VERSION "..\..\trunk\components\winTestMT\code\canApi\dbcFiles\canBus_01.dbc, created by Octave and generateRandomDbc.m on 21-Feb-2017"

NS_ :

BS_:

BU_: ECU

BO_ 1706 frame_1706: 8 Vector__XXX
  SG_ checksum_57_8 : 63|8@0+ (1.0,0.0) [0.0|255.0] "" ECU
  SG_ sig_2_29 : 2|29@1+ (1.0000000000000014E-12,0.0) [0.0|5.368709100000008E-4] "W" ECU
  SG_ sig_0_2 : 0|2@1+ (1.0,0.0) [0.0|3.0] "" ECU
  SG_ sig_42_14 : 42|14@1- (1.0,0.0) [-8192.0|8190.0] "" ECU
  SG_ sig_34_6 : 34|6@1+ (1.0,0.0) [0.0|62.0] "" ECU
  SG_ sig_33_2 : 33|2@0- (1.0,0.0) [-2.0|1.0] "" ECU

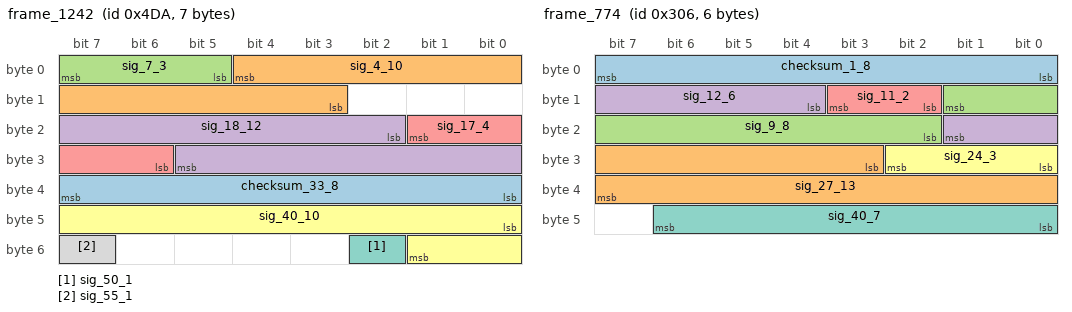
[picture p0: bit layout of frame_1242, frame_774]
BO_ 1242 frame_1242: 7 Vector__XXX
  SG_ checksum_33_8 : 39|8@0+ (1.0,0.0) [0.0|255.0] "" ECU
  SG_ sig_4_10 : 4|10@0- (1.0000000000000006E-6,0.0) [-5.120000000000003E-4|5.100000000000003E-4] "V" ECU
  SG_ sig_7_3 : 7|3@0- (1.0,0.0) [-4.0|2.0] "" ECU
  SG_ sig_18_12 : 18|12@1+ (0.0010000000000000002,-3.1622776601683795) [-3.1622776601683795|0.9317223398316217] "s" ECU
  SG_ sig_17_4 : 17|4@0- (1.0,0.0) [-8.0|6.0] "" ECU
  SG_ sig_40_10 : 40|10@1+ (1.0000000000000005E-4,0.03162277660168379) [0.03162277660168379|0.13382277660168385] "W" ECU
  SG_ sig_50_1 : 50|1@1+ (1.0,0.0) [0.0|1.0] "" ECU
  SG_ sig_55_1 : 55|1@0+ (1.0,0.0) [0.0|1.0] "" ECU

BO_ 774 frame_774: 6 Vector__XXX
  SG_ checksum_1_8 : 7|8@0+ (1.0,0.0) [0.0|255.0] "" ECU
  SG_ sig_27_13 : 27|13@1- (1.0000000000000005E-4,0.0) [-0.4096000000000002|0.4094000000000002] "W" ECU
  SG_ sig_9_8 : 9|8@0- (1.0000000000000006E-5,0.0) [-0.0012800000000000008|0.0012600000000000007] "kWh" ECU
  SG_ sig_12_6 : 12|6@1- (1.0,0.0) [-32.0|30.0] "" ECU
  SG_ sig_11_2 : 11|2@0- (1.0,0.0) [-2.0|1.0] "" ECU
  SG_ sig_24_3 : 24|3@1+ (1.0,0.0) [0.0|6.0] "" ECU
  SG_ sig_40_7 : 40|7@1- (0.010000000000000002,0.31622776601683794) [-0.3237722339831622|0.9362277660168381] "s" ECU

BO_ 2044 frame_2044: 4 ECU
  SG_ checksum_17_8 : 16|8@1+ (1.0,0.0) [0.0|255.0] "" Vector__XXX
  SG_ sig_0_14 : 0|14@1- (1.0000000000000008E-8,3.1622776601683795E-5) [-5.0297223398316274E-5|1.1352277660168385E-4] "m/s^2" Vector__XXX
  SG_ sig_15_2 : 15|2@0- (1.0,0.0) [-2.0|1.0] "" Vector__XXX
  SG_ sig_31_2 : 31|2@0- (1.0,0.0) [-2.0|1.0] "" Vector__XXX
  SG_ sig_24_1 : 24|1@1+ (1.0,0.0) [0.0|1.0] "" Vector__XXX

BO_ 1907 frame_1907: 7 Vector__XXX
  SG_ checksum_1_8 : 7|8@0+ (1.0,0.0) [0.0|255.0] "" ECU
  SG_ sig_31_1 : 31|1@0+ (1.0,0.0) [0.0|1.0] "" ECU
  SG_ sig_15_16 : 15|16@0- (0.0010000000000000002,-31.622776601683793) [-64.3907766016838|1.1432233983162128] "m/s^2" ECU
  SG_ sig_25_24 : 25|24@0- (1.0000000000000005E-4,316.22776601683796) [-522.6330339831625|1155.0883660168383] "W" ECU
  SG_ sig_30_5 : 30|5@0- (1.0,0.0) [-16.0|14.0] "" ECU

BO_ 594 frame_594: 7 Vector__XXX
  SG_ checksum_33_8 : 39|8@0+ (1.0,0.0) [0.0|255.0] "" ECU
  SG_ sig_5_25 : 5|25@1+ (0.0010000000000000002,0.0) [0.0|33554.43000000001] "s" ECU
  SG_ sig_1_4 : 1|4@1- (1.0,3.1622776601683795) [-4.83772233983162|9.16227766016838] "A" ECU
  SG_ sig_0_1 : 0|1@0+ (1.0,0.0) [0.0|1.0] "" ECU
  SG_ sig_30_2 : 30|2@1- (1.0,0.0) [-2.0|1.0] "" ECU
  SG_ sig_47_16 : 47|16@0- (1.0000000000000007E-7,0.0) [-0.0032768000000000025|0.0032766000000000023] "m/s^2" ECU

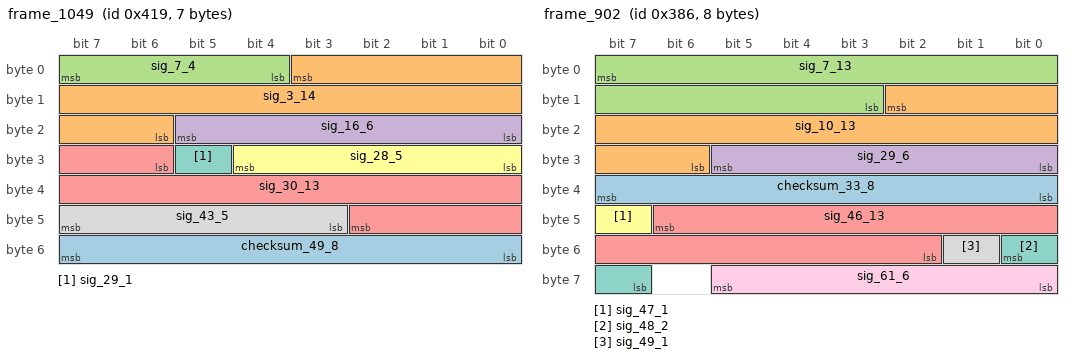
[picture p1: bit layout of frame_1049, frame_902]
BO_ 1049 frame_1049: 7 ECU
  SG_ checksum_49_8 : 48|8@1+ (1.0,0.0) [0.0|255.0] "" Vector__XXX
  SG_ sig_3_14 : 3|14@0+ (0.0010000000000000002,3.1622776601683795) [3.1622776601683795|19.544277660168383] "A" Vector__XXX
  SG_ sig_7_4 : 7|4@0+ (1.0,0.0) [0.0|14.0] "" Vector__XXX
  SG_ sig_16_6 : 16|6@1- (1.0,0.0) [-32.0|30.0] "" Vector__XXX
  SG_ sig_30_13 : 30|13@1+ (1.0,3162.2776601683795) [3162.2776601683795|11352.27766016838] "s" Vector__XXX
  SG_ sig_28_5 : 28|5@0- (1.0,0.0) [-16.0|14.0] "" Vector__XXX
  SG_ sig_29_1 : 29|1@0+ (1.0,0.0) [0.0|1.0] "" Vector__XXX
  SG_ sig_43_5 : 43|5@1+ (100.0,0.0) [0.0|3000.0] "km/h" Vector__XXX

BO_ 1207 frame_1207: 7 Vector__XXX
  SG_ checksum_1_8 : 0|8@1+ (1.0,0.0) [0.0|255.0] "" ECU
  SG_ sig_19_31 : 19|31@1- (1.0000000000000011E-10,0.0) [-0.10737418240000011|0.10737418220000011] "V" ECU
  SG_ sig_9_10 : 9|10@1- (100.0,0.0) [-51200.0|51000.0] "km/h" ECU
  SG_ sig_8_1 : 8|1@0+ (1.0,0.0) [0.0|1.0] "" ECU
  SG_ sig_55_4 : 55|4@0- (1.0000000000000006E-6,-3.162277660168379E-6) [-1.1162277660168384E-5|2.8377223398316243E-6] "km/h" ECU

BO_ 902 frame_902: 8 Vector__XXX
  SG_ checksum_33_8 : 39|8@0+ (1.0,0.0) [0.0|255.0] "" ECU
  SG_ sig_10_13 : 10|13@0- (1.0000000000000009E-9,3.162277660168379E-6) [-9.337223398316245E-7|7.256277660168383E-6] "W" ECU
  SG_ sig_7_13 : 7|13@0- (1.0,0.0) [-4096.0|4094.0] "" ECU
  SG_ sig_29_6 : 29|6@0+ (0.1,3.1622776601683795) [3.1622776601683795|9.36227766016838] "kWh" ECU
  SG_ sig_46_13 : 46|13@0+ (0.1,0.0) [0.0|819.0] "m/s^2" ECU
  SG_ sig_47_1 : 47|1@0+ (1.0,0.0) [0.0|1.0] "" ECU
  SG_ sig_48_2 : 48|2@0+ (1.0,0.0) [0.0|3.0] "" ECU
  SG_ sig_49_1 : 49|1@0+ (1.0,0.0) [0.0|1.0] "" ECU
  SG_ sig_61_6 : 61|6@0+ (1.0,0.0) [0.0|62.0] "" ECU

BO_ 1834 frame_1834: 6 ECU
  SG_ checksum_17_8 : 16|8@1+ (1.0,0.0) [0.0|255.0] "" Vector__XXX
  SG_ sig_7_16 : 7|16@0+ (1.0000000000000009E-9,0.0) [0.0|6.553400000000005E-5] "m/s^2" Vector__XXX
  SG_ sig_28_20 : 28|20@0+ (1.0000000000000007E-7,-0.03162277660168379) [-0.03162277660168379|0.07323462339831628] "W" Vector__XXX
  SG_ sig_29_3 : 29|3@1+ (1.0,0.0) [0.0|6.0] "" Vector__XXX
  SG_ sig_40_1 : 40|1@1+ (1.0,0.0) [0.0|1.0] "" Vector__XXX

BO_ 609 frame_609: 5 Vector__XXX
  SG_ checksum_1_8 : 7|8@0+ (1.0,0.0) [0.0|255.0] "" ECU
  SG_ sig_22_5 : 22|5@0- (1.0,0.0) [-16.0|14.0] "" ECU
  SG_ sig_8_8 : 8|8@1- (10.0,0.0) [-1280.0|1260.0] "km/h" ECU
  SG_ sig_16_2 : 16|2@1+ (1.0,0.0) [0.0|3.0] "" ECU
  SG_ sig_23_16 : 23|16@1+ (1.0,0.0) [0.0|65534.0] "" ECU

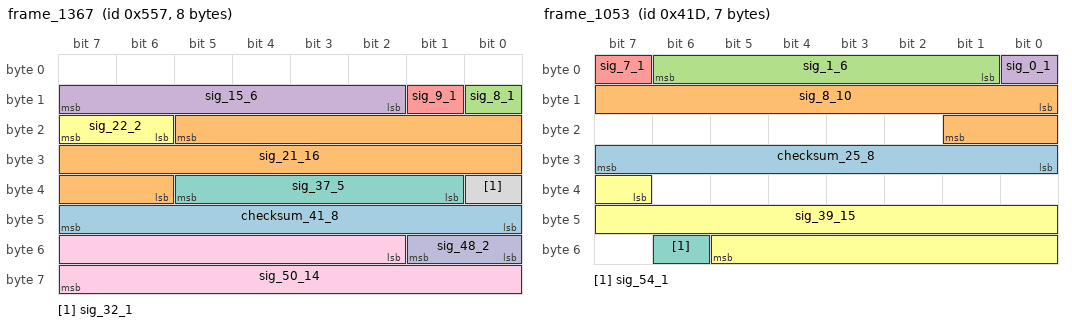
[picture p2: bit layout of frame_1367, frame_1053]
BO_ 1367 frame_1367: 8 Vector__XXX
  SG_ checksum_41_8 : 40|8@1+ (1.0,0.0) [0.0|255.0] "" ECU
  SG_ sig_21_16 : 21|16@0- (1.0000000000000005E-4,0.0) [-3.2768000000000015|3.2766000000000015] "W" ECU
  SG_ sig_8_1 : 8|1@1+ (1.0,0.0) [0.0|1.0] "" ECU
  SG_ sig_15_6 : 15|6@0- (100.0,3162.2776601683795) [-37.7223398316205|6162.27766016838] "s" ECU
  SG_ sig_9_1 : 9|1@0+ (1.0,0.0) [0.0|1.0] "" ECU
  SG_ sig_22_2 : 22|2@1+ (1.0,0.0) [0.0|3.0] "" ECU
  SG_ sig_37_5 : 37|5@0+ (1.0,0.0) [0.0|30.0] "" ECU
  SG_ sig_32_1 : 32|1@1+ (1.0,0.0) [0.0|1.0] "" ECU
  SG_ sig_50_14 : 50|14@1+ (0.010000000000000002,0.0) [0.0|163.82000000000002] "m/s^2" ECU
  SG_ sig_48_2 : 48|2@1- (1.0,0.0) [-2.0|1.0] "" ECU

BO_ 1053 frame_1053: 7 ECU
  SG_ checksum_25_8 : 24|8@1+ (1.0,0.0) [0.0|255.0] "" Vector__XXX
  SG_ sig_8_10 : 8|10@1- (1.0,0.0) [-512.0|510.0] "" Vector__XXX
  SG_ sig_1_6 : 1|6@1- (1.0,0.0) [-32.0|30.0] "" Vector__XXX
  SG_ sig_0_1 : 0|1@1+ (1.0,0.0) [0.0|1.0] "" Vector__XXX
  SG_ sig_7_1 : 7|1@1+ (1.0,0.0) [0.0|1.0] "" Vector__XXX
  SG_ sig_39_15 : 39|15@1+ (1.0000000000000005E-4,0.0) [0.0|3.2766000000000015] "m/s^2" Vector__XXX
  SG_ sig_54_1 : 54|1@1+ (1.0,0.0) [0.0|1.0] "" Vector__XXX

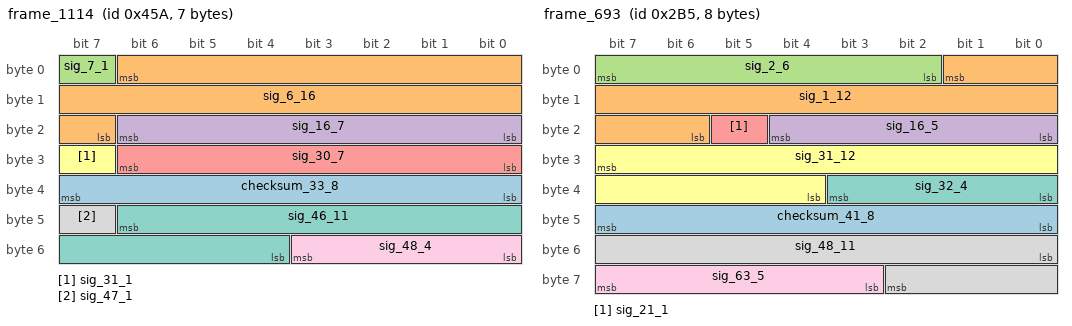
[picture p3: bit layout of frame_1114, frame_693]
BO_ 1114 frame_1114: 7 Vector__XXX
  SG_ checksum_33_8 : 32|8@1+ (1.0,0.0) [0.0|255.0] "" ECU
  SG_ sig_6_16 : 6|16@0- (1.0000000000000007E-7,0.0) [-0.0032768000000000025|0.0032766000000000023] "s" ECU
  SG_ sig_7_1 : 7|1@1+ (1.0,0.0) [0.0|1.0] "" ECU
  SG_ sig_16_7 : 16|7@1- (0.0010000000000000002,0.0) [-0.06400000000000002|0.06200000000000001] "kWh" ECU
  SG_ sig_30_7 : 30|7@0+ (1.0000000000000005E-4,0.0) [0.0|0.012600000000000005] "V" ECU
  SG_ sig_31_1 : 31|1@1+ (1.0,0.0) [0.0|1.0] "" ECU
  SG_ sig_46_11 : 46|11@0+ (1.0000000000000008E-8,0.0) [0.0|2.0460000000000018E-5] "m/s^2" ECU
  SG_ sig_47_1 : 47|1@0+ (1.0,0.0) [0.0|1.0] "" ECU
  SG_ sig_48_4 : 48|4@1+ (10000.0,-31622.776601683792) [-31622.776601683792|108377.22339831622] "V" ECU

BO_ 693 frame_693: 8 ECU
  SG_ checksum_41_8 : 40|8@1+ (1.0,0.0) [0.0|255.0] "" Vector__XXX
  SG_ sig_1_12 : 1|12@0- (1.0000000000000006E-6,0.0) [-0.002048000000000001|0.0020460000000000014] "V" Vector__XXX
  SG_ sig_2_6 : 2|6@1- (1.0000000000000006E-6,-3.1622776601683795E-5) [-6.362277660168381E-5|-1.6227766016837776E-6] "m/s^2" Vector__XXX
  SG_ sig_16_5 : 16|5@1- (1.0,0.0) [-16.0|14.0] "" Vector__XXX
  SG_ sig_21_1 : 21|1@0+ (1.0,0.0) [0.0|1.0] "" Vector__XXX
  SG_ sig_31_12 : 31|12@0+ (0.1,0.0) [0.0|409.40000000000003] "V" Vector__XXX
  SG_ sig_32_4 : 32|4@1- (1000.0,0.0) [-8000.0|6000.0] "kWh" Vector__XXX
  SG_ sig_48_11 : 48|11@1- (1.0,0.0) [-1024.0|1022.0] "" Vector__XXX
  SG_ sig_63_5 : 63|5@0+ (0.010000000000000002,0.0) [0.0|0.30000000000000004] "m/s^2" Vector__XXX

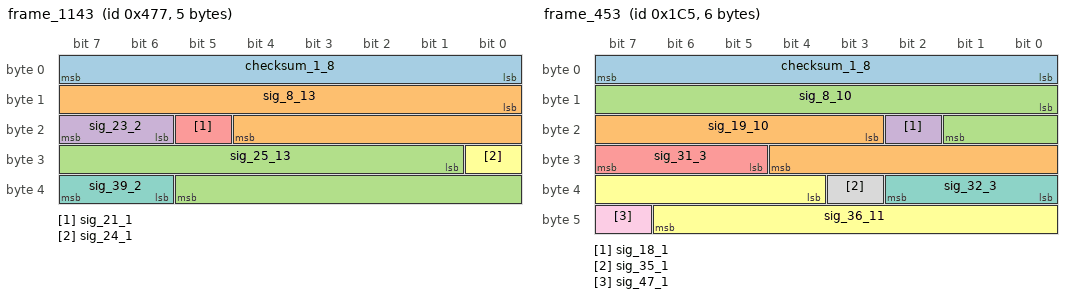
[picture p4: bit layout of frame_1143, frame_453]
BO_ 1143 frame_1143: 5 ECU
  SG_ checksum_1_8 : 7|8@0+ (1.0,0.0) [0.0|255.0] "" Vector__XXX
  SG_ sig_8_13 : 8|13@1+ (1.0000000000000005E-4,0.31622776601683794) [0.31622776601683794|1.1352277660168384] "A" Vector__XXX
  SG_ sig_25_13 : 25|13@1- (1.0000000000000009E-9,0.0) [-4.096000000000004E-6|4.0940000000000035E-6] "m/s^2" Vector__XXX
  SG_ sig_23_2 : 23|2@0- (1.0,0.0) [-2.0|1.0] "" Vector__XXX
  SG_ sig_21_1 : 21|1@0+ (1.0,0.0) [0.0|1.0] "" Vector__XXX
  SG_ sig_24_1 : 24|1@1+ (1.0,0.0) [0.0|1.0] "" Vector__XXX
  SG_ sig_39_2 : 39|2@0- (1.0,0.0) [-2.0|1.0] "" Vector__XXX

BO_ 667 frame_667: 7 Vector__XXX
  SG_ checksum_1_8 : 0|8@1+ (1.0,0.0) [0.0|255.0] "" ECU
  SG_ sig_22_35 : 22|35@0+ (1.0000000000000007E-7,3162.2776601683795) [3162.2776601683795|6598.251496768382] "A" ECU
  SG_ sig_9_6 : 9|6@1+ (0.1,3.1622776601683795) [3.1622776601683795|9.36227766016838] "s" ECU
  SG_ sig_48_3 : 48|3@1- (1.0,0.0) [-4.0|2.0] "" ECU

BO_ 453 frame_453: 6 ECU
  SG_ checksum_1_8 : 7|8@0+ (1.0,0.0) [0.0|255.0] "" Vector__XXX
  SG_ sig_19_10 : 19|10@1+ (1.0000000000000007E-7,-3.1622776601683795E-5) [-3.1622776601683795E-5|7.057722339831628E-5] "A" Vector__XXX
  SG_ sig_8_10 : 8|10@1+ (1.0,0.0) [0.0|1022.0] "" Vector__XXX
  SG_ sig_18_1 : 18|1@1+ (1.0,0.0) [0.0|1.0] "" Vector__XXX
  SG_ sig_31_3 : 31|3@0- (1.0,0.0) [-4.0|2.0] "" Vector__XXX
  SG_ sig_36_11 : 36|11@1+ (1.0000000000000006E-5,-0.0031622776601683794) [-0.0031622776601683794|0.017297722339831633] "m/s^2" Vector__XXX
  SG_ sig_32_3 : 32|3@1- (1.0,0.0) [-4.0|2.0] "" Vector__XXX
  SG_ sig_35_1 : 35|1@0+ (1.0,0.0) [0.0|1.0] "" Vector__XXX
  SG_ sig_47_1 : 47|1@0+ (1.0,0.0) [0.0|1.0] "" Vector__XXX

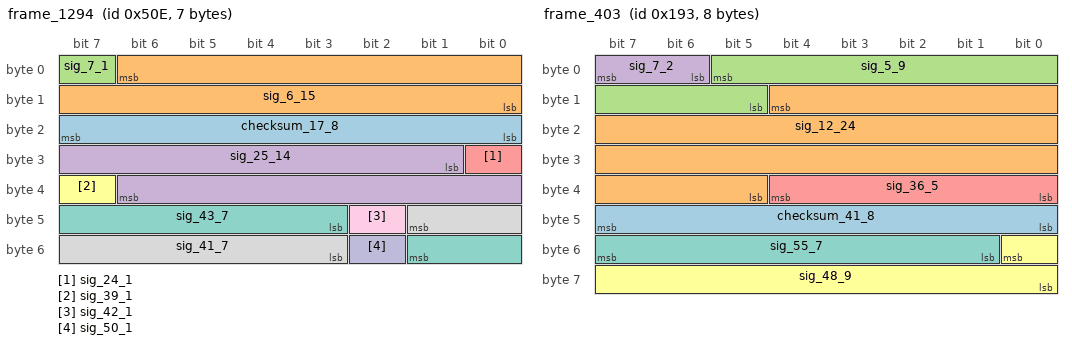
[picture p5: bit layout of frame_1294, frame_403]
BO_ 1294 frame_1294: 7 Vector__XXX
  SG_ checksum_17_8 : 23|8@0+ (1.0,0.0) [0.0|255.0] "" ECU
  SG_ sig_6_15 : 6|15@0- (0.010000000000000002,0.0) [-163.84000000000003|163.82000000000002] "V" ECU
  SG_ sig_7_1 : 7|1@0+ (1.0,0.0) [0.0|1.0] "" ECU
  SG_ sig_25_14 : 25|14@1+ (0.010000000000000002,0.0) [0.0|163.82000000000002] "kWh" ECU
  SG_ sig_24_1 : 24|1@1+ (1.0,0.0) [0.0|1.0] "" ECU
  SG_ sig_39_1 : 39|1@0+ (1.0,0.0) [0.0|1.0] "" ECU
  SG_ sig_43_7 : 43|7@1- (1.0000000000000005E-4,-0.0031622776601683794) [-0.009562277660168383|0.003037722339831623] "m/s^2" ECU
  SG_ sig_41_7 : 41|7@0- (1.0000000000000006E-6,0.0) [-6.400000000000004E-5|6.200000000000004E-5] "m/s^2" ECU
  SG_ sig_42_1 : 42|1@0+ (1.0,0.0) [0.0|1.0] "" ECU
  SG_ sig_50_1 : 50|1@0+ (1.0,0.0) [0.0|1.0] "" ECU

BO_ 403 frame_403: 8 ECU
  SG_ checksum_41_8 : 47|8@0+ (1.0,0.0) [0.0|255.0] "" Vector__XXX
  SG_ sig_12_24 : 12|24@0+ (1.0000000000000014E-12,-3.162277660168379E-6) [-3.162277660168379E-6|1.3614936339831645E-5] "s" Vector__XXX
  SG_ sig_5_9 : 5|9@0- (1.0000000000000007E-7,0.0) [-2.560000000000002E-5|2.5400000000000018E-5] "m/s^2" Vector__XXX
  SG_ sig_7_2 : 7|2@0+ (1.0,0.0) [0.0|3.0] "" Vector__XXX
  SG_ sig_36_5 : 36|5@0- (1.0,0.0) [-16.0|14.0] "" Vector__XXX
  SG_ sig_48_9 : 48|9@0+ (1.0000000000000005E-4,-0.03162277660168379) [-0.03162277660168379|0.019377223398316233] "W" Vector__XXX
  SG_ sig_55_7 : 55|7@0+ (1.0,-31.622776601683793) [-31.622776601683793|94.3772233983162] "V" Vector__XXX

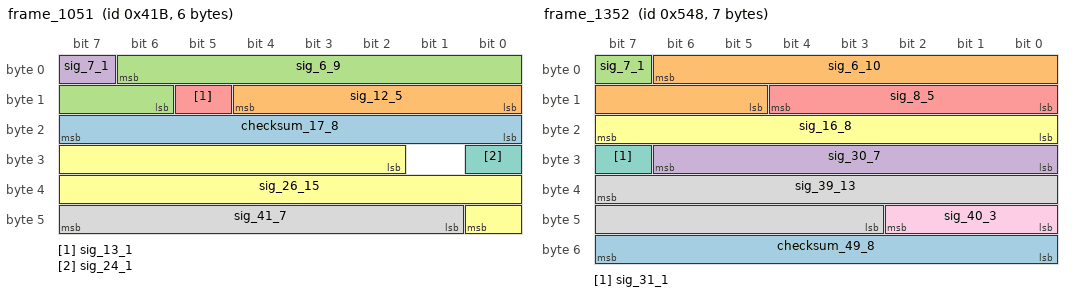
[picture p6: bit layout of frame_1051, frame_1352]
BO_ 1051 frame_1051: 6 Vector__XXX
  SG_ checksum_17_8 : 23|8@0+ (1.0,0.0) [0.0|255.0] "" ECU
  SG_ sig_12_5 : 12|5@0+ (1.0,0.0) [0.0|30.0] "km/h" ECU
  SG_ sig_6_9 : 6|9@0- (1.0000000000000007E-7,0.0) [-2.560000000000002E-5|2.5400000000000018E-5] "m/s^2" ECU
  SG_ sig_7_1 : 7|1@0+ (1.0,0.0) [0.0|1.0] "" ECU
  SG_ sig_13_1 : 13|1@0+ (1.0,0.0) [0.0|1.0] "" ECU
  SG_ sig_26_15 : 26|15@1- (1.0,0.0) [-16384.0|16382.0] "" ECU
  SG_ sig_24_1 : 24|1@0+ (1.0,0.0) [0.0|1.0] "" ECU
  SG_ sig_41_7 : 41|7@1+ (1.0000000000000005E-4,0.0031622776601683794) [0.0031622776601683794|0.015762277660168383] "A" ECU

BO_ 1352 frame_1352: 7 Vector__XXX
  SG_ checksum_49_8 : 48|8@1+ (1.0,0.0) [0.0|255.0] "" ECU
  SG_ sig_6_10 : 6|10@0+ (1.0000000000000006E-6,0.0) [0.0|0.0010220000000000006] "W" ECU
  SG_ sig_7_1 : 7|1@0+ (1.0,0.0) [0.0|1.0] "" ECU
  SG_ sig_30_7 : 30|7@0+ (1.0,0.0) [0.0|126.0] "" ECU
  SG_ sig_8_5 : 8|5@1+ (1.0,0.0) [0.0|30.0] "kWh" ECU
  SG_ sig_16_8 : 16|8@1+ (0.010000000000000002,0.31622776601683794) [0.31622776601683794|2.8562277660168385] "m/s^2" ECU
  SG_ sig_31_1 : 31|1@0+ (1.0,0.0) [0.0|1.0] "" ECU
  SG_ sig_39_13 : 39|13@0- (1.0000000000000007E-7,-3.1622776601683794E-4) [-7.258277660168382E-4|9.317223398316236E-5] "km/h" ECU
  SG_ sig_40_3 : 40|3@1- (1.0,0.0) [-4.0|2.0] "" ECU

BO_ 1140 frame_1140: 7 Vector__XXX
  SG_ checksum_33_8 : 32|8@1+ (1.0,0.0) [0.0|255.0] "" ECU
  SG_ sig_16_14 : 16|14@1- (1.0000000000000005E-4,0.31622776601683794) [-0.5029722339831624|1.1352277660168384] "kWh" ECU
  SG_ sig_3_11 : 3|11@1- (1.0,0.0) [-1024.0|1022.0] "" ECU
  SG_ sig_0_3 : 0|3@0+ (1.0,0.0) [0.0|6.0] "" ECU
  SG_ sig_40_16 : 40|16@1- (1.0000000000000007E-7,0.0) [-0.0032768000000000025|0.0032766000000000023] "A" ECU

BO_ 652 frame_652: 6 Vector__XXX
  SG_ checksum_1_8 : 7|8@0+ (1.0,0.0) [0.0|255.0] "" ECU
  SG_ sig_10_2 : 10|2@1+ (1.0,0.0) [0.0|3.0] "" ECU
  SG_ sig_9_2 : 9|2@0+ (1.0,0.0) [0.0|3.0] "" ECU
  SG_ sig_34_11 : 34|11@1+ (1.0000000000000006E-5,0.0031622776601683794) [0.0031622776601683794|0.023622277660168393] "W" ECU
  SG_ sig_32_2 : 32|2@1- (1.0,0.0) [-2.0|1.0] "" ECU
  SG_ sig_47_3 : 47|3@0- (1.0,0.0) [-4.0|2.0] "" ECU

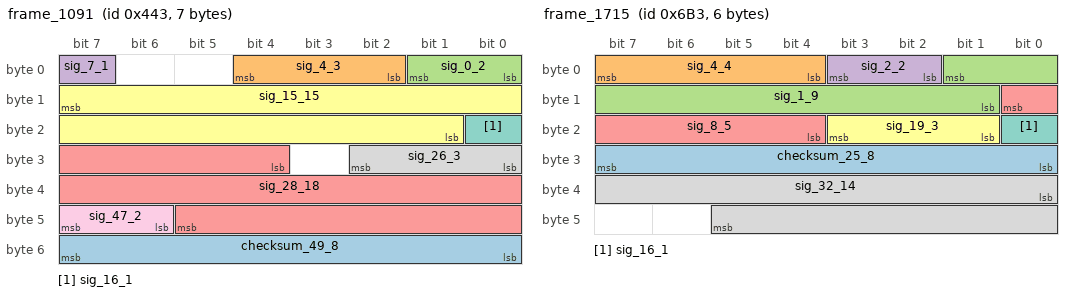
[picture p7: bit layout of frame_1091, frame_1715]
BO_ 1091 frame_1091: 7 Vector__XXX
  SG_ checksum_49_8 : 55|8@0+ (1.0,0.0) [0.0|255.0] "" ECU
  SG_ sig_4_3 : 4|3@0+ (1.0,0.0) [0.0|6.0] "" ECU
  SG_ sig_0_2 : 0|2@1+ (1.0,0.0) [0.0|3.0] "" ECU
  SG_ sig_7_1 : 7|1@0+ (1.0,0.0) [0.0|1.0] "" ECU
  SG_ sig_28_18 : 28|18@1- (1.0000000000000008E-8,3.1622776601683794E-4) [-9.944922339831632E-4|0.001626927766016839] "V" ECU
  SG_ sig_15_15 : 15|15@0- (1.0,0.0) [-16384.0|16382.0] "" ECU
  SG_ sig_16_1 : 16|1@0+ (1.0,0.0) [0.0|1.0] "" ECU
  SG_ sig_26_3 : 26|3@0- (1.0,0.0) [-4.0|2.0] "" ECU
  SG_ sig_47_2 : 47|2@0- (1.0,0.0) [-2.0|1.0] "" ECU

BO_ 1715 frame_1715: 6 Vector__XXX
  SG_ checksum_25_8 : 31|8@0+ (1.0,0.0) [0.0|255.0] "" ECU
  SG_ sig_4_4 : 4|4@1- (10000.0,-31622.776601683792) [-111622.77660168378|28377.223398316208] "kWh" ECU
  SG_ sig_1_9 : 1|9@0+ (1.0,0.0) [0.0|510.0] "" ECU
  SG_ sig_2_2 : 2|2@1+ (1.0,0.0) [0.0|3.0] "" ECU
  SG_ sig_8_5 : 8|5@0+ (1.0000000000000006E-5,3.1622776601683794E-4) [3.1622776601683794E-4|6.162277660168381E-4] "km/h" ECU
  SG_ sig_19_3 : 19|3@0- (1.0,0.0) [-4.0|2.0] "" ECU
  SG_ sig_16_1 : 16|1@1+ (1.0,0.0) [0.0|1.0] "" ECU
  SG_ sig_32_14 : 32|14@1+ (1.0,-3162.2776601683795) [-3162.2776601683795|13219.72233983162] "V" ECU

BO_ 766 frame_766: 7 ECU
  SG_ checksum_9_8 : 8|8@1+ (1.0,0.0) [0.0|255.0] "" Vector__XXX
  SG_ sig_0_1 : 0|1@1+ (1.0,0.0) [0.0|1.0] "" Vector__XXX
  SG_ sig_17_39 : 17|39@1+ (1.0000000000000007E-7,-31622.776601683792) [-31622.776601683792|23352.804786916247] "kWh" Vector__XXX
  SG_ sig_16_1 : 16|1@1+ (1.0,0.0) [0.0|1.0] "" Vector__XXX

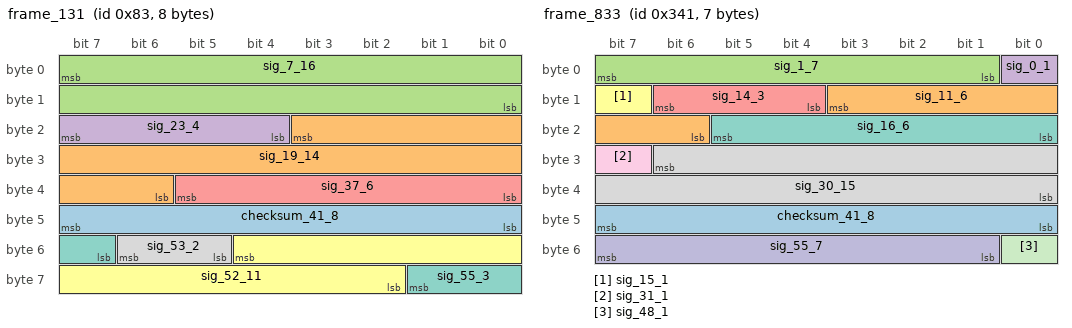
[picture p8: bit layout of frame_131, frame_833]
BO_ 131 frame_131: 8 Vector__XXX
  SG_ checksum_41_8 : 40|8@1+ (1.0,0.0) [0.0|255.0] "" ECU
  SG_ sig_19_14 : 19|14@0+ (1.0000000000000009E-9,0.0) [0.0|1.6382000000000014E-5] "V" ECU
  SG_ sig_7_16 : 7|16@0+ (1.0,0.0) [0.0|65534.0] "" ECU
  SG_ sig_23_4 : 23|4@0- (0.010000000000000002,0.03162277660168379) [-0.048377223398316224|0.0916227766016838] "m/s^2" ECU
  SG_ sig_37_6 : 37|6@0- (0.1,0.0) [-3.2|3.0] "W" ECU
  SG_ sig_52_11 : 52|11@0+ (1.0,0.0) [0.0|2046.0] "" ECU
  SG_ sig_55_3 : 55|3@1- (1.0,0.0) [-4.0|2.0] "" ECU
  SG_ sig_53_2 : 53|2@1- (1.0,0.0) [-2.0|1.0] "" ECU

BO_ 1271 frame_1271: 6 ECU
  SG_ checksum_41_8 : 40|8@1+ (1.0,0.0) [0.0|255.0] "" Vector__XXX
  SG_ sig_5_37 : 5|37@0- (1.0000000000000011E-10,-3.1622776601683795) [-10.034225333768386|3.709670013231628] "km/h" Vector__XXX
  SG_ sig_7_2 : 7|2@0- (1.0,0.0) [-2.0|1.0] "" Vector__XXX
  SG_ sig_32_1 : 32|1@0+ (1.0,0.0) [0.0|1.0] "" Vector__XXX

BO_ 332 frame_332: 5 ECU
  SG_ checksum_17_8 : 23|8@0+ (1.0,0.0) [0.0|255.0] "" Vector__XXX
  SG_ sig_3_7 : 3|7@1+ (1.0000000000000007E-7,-3.162277660168379E-6) [-3.162277660168379E-6|9.43772233983163E-6] "km/h" Vector__XXX
  SG_ sig_1_8 : 1|8@0- (1.0000000000000006E-5,-3.1622776601683794E-4) [-0.0015962277660168387|9.437722339831628E-4] "W" Vector__XXX
  SG_ sig_2_1 : 2|1@0+ (1.0,0.0) [0.0|1.0] "" Vector__XXX
  SG_ sig_31_16 : 31|16@0- (1.0,0.0) [-32768.0|32766.0] "" Vector__XXX

BO_ 602 frame_602: 7 ECU
  SG_ checksum_1_8 : 0|8@1+ (1.0,0.0) [0.0|255.0] "" Vector__XXX
  SG_ sig_40_15 : 40|15@1+ (1.0000000000000006E-5,0.0) [0.0|0.3276600000000002] "V" Vector__XXX
  SG_ sig_9_12 : 9|12@1+ (0.010000000000000002,0.0) [0.0|40.940000000000005] "km/h" Vector__XXX
  SG_ sig_8_1 : 8|1@1+ (1.0,0.0) [0.0|1.0] "" Vector__XXX
  SG_ sig_21_19 : 21|19@1+ (1.000000000000001E-11,0.0) [0.0|5.242860000000006E-6] "kWh" Vector__XXX
  SG_ sig_55_1 : 55|1@1+ (1.0,0.0) [0.0|1.0] "" Vector__XXX

BO_ 833 frame_833: 7 Vector__XXX
  SG_ checksum_41_8 : 47|8@0+ (1.0,0.0) [0.0|255.0] "" ECU
  SG_ sig_11_6 : 11|6@0- (1.0,0.0) [-32.0|30.0] "" ECU
  SG_ sig_1_7 : 1|7@1+ (1.0,0.0) [0.0|126.0] "" ECU
  SG_ sig_0_1 : 0|1@1+ (1.0,0.0) [0.0|1.0] "" ECU
  SG_ sig_14_3 : 14|3@0- (1.0,0.0) [-4.0|2.0] "" ECU
  SG_ sig_15_1 : 15|1@0+ (1.0,0.0) [0.0|1.0] "" ECU
  SG_ sig_16_6 : 16|6@1- (1.0,0.0) [-32.0|30.0] "" ECU
  SG_ sig_30_15 : 30|15@0+ (0.0010000000000000002,31.622776601683793) [31.622776601683793|64.3887766016838] "m/s^2" ECU
  SG_ sig_31_1 : 31|1@0+ (1.0,0.0) [0.0|1.0] "" ECU
  SG_ sig_55_7 : 55|7@0- (1.0,0.0) [-64.0|62.0] "" ECU
  SG_ sig_48_1 : 48|1@0+ (1.0,0.0) [0.0|1.0] "" ECU

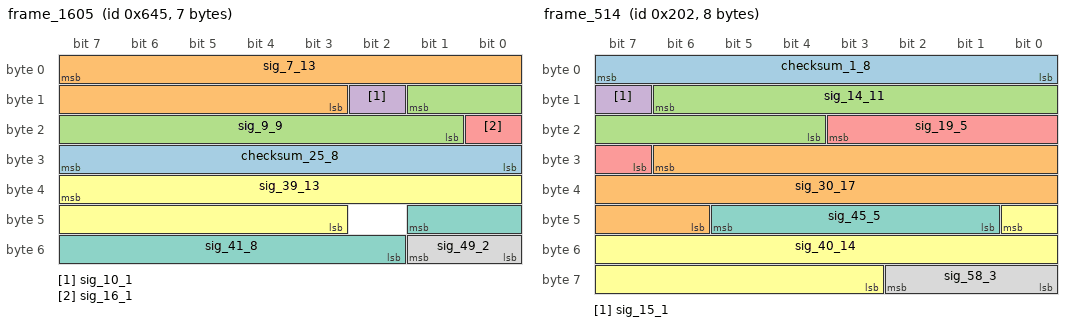
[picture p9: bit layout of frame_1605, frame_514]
BO_ 1605 frame_1605: 7 ECU
  SG_ checksum_25_8 : 31|8@0+ (1.0,0.0) [0.0|255.0] "" Vector__XXX
  SG_ sig_7_13 : 7|13@0+ (1.0,0.0) [0.0|8190.0] "" Vector__XXX
  SG_ sig_9_9 : 9|9@0+ (1.0,0.0) [0.0|510.0] "" Vector__XXX
  SG_ sig_10_1 : 10|1@0+ (1.0,0.0) [0.0|1.0] "" Vector__XXX
  SG_ sig_16_1 : 16|1@0+ (1.0,0.0) [0.0|1.0] "" Vector__XXX
  SG_ sig_39_13 : 39|13@0- (1.0000000000000008E-8,0.0) [-4.0960000000000035E-5|4.094000000000003E-5] "W" Vector__XXX
  SG_ sig_41_8 : 41|8@0- (1.0,0.0) [-128.0|126.0] "" Vector__XXX
  SG_ sig_49_2 : 49|2@0+ (1.0,0.0) [0.0|3.0] "" Vector__XXX

BO_ 514 frame_514: 8 Vector__XXX
  SG_ checksum_1_8 : 7|8@0+ (1.0,0.0) [0.0|255.0] "" ECU
  SG_ sig_30_17 : 30|17@0- (1.0,0.0) [-65536.0|65534.0] "" ECU
  SG_ sig_14_11 : 14|11@0- (1.0,0.0) [-1024.0|1022.0] "" ECU
  SG_ sig_15_1 : 15|1@0+ (1.0,0.0) [0.0|1.0] "" ECU
  SG_ sig_19_5 : 19|5@0+ (1000.0,-31622.776601683792) [-31622.776601683792|-1622.7766016837923] "m/s^2" ECU
  SG_ sig_40_14 : 40|14@0+ (10.0,31622.776601683792) [31622.776601683792|195442.77660168378] "m/s^2" ECU
  SG_ sig_45_5 : 45|5@0- (0.010000000000000002,0.0) [-0.16000000000000003|0.14] "V" ECU
  SG_ sig_58_3 : 58|3@0+ (1.0,0.0) [0.0|6.0] "" ECU

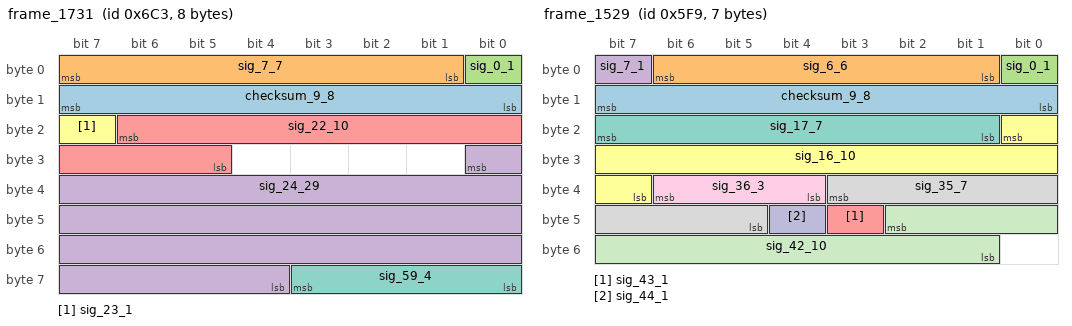
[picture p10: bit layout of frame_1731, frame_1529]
BO_ 1731 frame_1731: 8 ECU
  SG_ checksum_9_8 : 15|8@0+ (1.0,0.0) [0.0|255.0] "" Vector__XXX
  SG_ sig_7_7 : 7|7@0+ (1.0000000000000006E-6,-3.1622776601683795E-5) [-3.1622776601683795E-5|9.437722339831629E-5] "V" Vector__XXX
  SG_ sig_0_1 : 0|1@0+ (1.0,0.0) [0.0|1.0] "" Vector__XXX
  SG_ sig_24_29 : 24|29@0- (1.0000000000000014E-14,-3.162277660168379E-6) [-5.846632220168383E-6|-4.779231201683755E-7] "s" Vector__XXX
  SG_ sig_22_10 : 22|10@0- (1.0,0.0) [-512.0|510.0] "" Vector__XXX
  SG_ sig_23_1 : 23|1@0+ (1.0,0.0) [0.0|1.0] "" Vector__XXX
  SG_ sig_59_4 : 59|4@0+ (0.1,0.0) [0.0|1.4000000000000001] "V" Vector__XXX

BO_ 1529 frame_1529: 7 ECU
  SG_ checksum_9_8 : 15|8@0+ (1.0,0.0) [0.0|255.0] "" Vector__XXX
  SG_ sig_6_6 : 6|6@0- (1.0,0.0) [-32.0|30.0] "" Vector__XXX
  SG_ sig_0_1 : 0|1@1+ (1.0,0.0) [0.0|1.0] "" Vector__XXX
  SG_ sig_7_1 : 7|1@1+ (1.0,0.0) [0.0|1.0] "" Vector__XXX
  SG_ sig_43_1 : 43|1@0+ (1.0,0.0) [0.0|1.0] "" Vector__XXX
  SG_ sig_16_10 : 16|10@0+ (0.1,31.622776601683793) [31.622776601683793|133.82277660168378] "V" Vector__XXX
  SG_ sig_17_7 : 17|7@1+ (1.0,0.0) [0.0|126.0] "" Vector__XXX
  SG_ sig_35_7 : 35|7@0+ (1.0000000000000006E-5,-3.1622776601683794E-4) [-3.1622776601683794E-4|9.437722339831628E-4] "km/h" Vector__XXX
  SG_ sig_36_3 : 36|3@1- (1.0,0.0) [-4.0|2.0] "" Vector__XXX
  SG_ sig_44_1 : 44|1@0+ (1.0,0.0) [0.0|1.0] "" Vector__XXX
  SG_ sig_42_10 : 42|10@0+ (1.0000000000000007E-7,0.0) [0.0|1.0220000000000007E-4] "W" Vector__XXX

BO_ 417 frame_417: 6 Vector__XXX
  SG_ checksum_9_8 : 15|8@0+ (1.0,0.0) [0.0|255.0] "" ECU
  SG_ sig_7_8 : 7|8@0+ (0.1,-3.1622776601683795) [-3.1622776601683795|22.237722339831624] "kWh" ECU
  SG_ sig_16_14 : 16|14@0- (0.1,316.22776601683796) [-502.9722339831621|1135.227766016838] "km/h" ECU
  SG_ sig_21_5 : 21|5@0+ (1.0000000000000005E-4,0.0) [0.0|0.0030000000000000014] "V" ECU
  SG_ sig_23_2 : 23|2@0- (1.0,0.0) [-2.0|1.0] "" ECU
  SG_ sig_34_9 : 34|9@0+ (1.0,0.0) [0.0|510.0] "" ECU
  SG_ sig_41_2 : 41|2@0+ (1.0,0.0) [0.0|3.0] "" ECU

BO_ 808 frame_808: 6 ECU
  SG_ checksum_17_8 : 16|8@1+ (1.0,0.0) [0.0|255.0] "" Vector__XXX
  SG_ sig_2_11 : 2|11@1- (1.0,0.0) [-1024.0|1022.0] "" Vector__XXX
  SG_ sig_0_2 : 0|2@1+ (1.0,0.0) [0.0|3.0] "" Vector__XXX
  SG_ sig_28_15 : 28|15@1- (0.0010000000000000002,31.622776601683793) [15.238776601683789|48.0047766016838] "m/s^2" Vector__XXX
  SG_ sig_24_3 : 24|3@1- (1.0,0.0) [-4.0|2.0] "" Vector__XXX
  SG_ sig_27_1 : 27|1@1+ (1.0,0.0) [0.0|1.0] "" Vector__XXX
  SG_ sig_43_5 : 43|5@1+ (1.0,0.0) [0.0|30.0] "" Vector__XXX

BO_ 1181 frame_1181: 6 ECU
  SG_ checksum_1_8 : 0|8@1+ (1.0,0.0) [0.0|255.0] "" Vector__XXX
  SG_ sig_10_19 : 10|19@0- (1.0000000000000008E-8,-0.0031622776601683794) [-0.005783717660168382|-5.40857660168377E-4] "W" Vector__XXX
  SG_ sig_32_13 : 32|13@1+ (1.0,0.0) [0.0|8190.0] "" Vector__XXX
  SG_ sig_47_3 : 47|3@0+ (1.0,0.0) [0.0|6.0] "" Vector__XXX

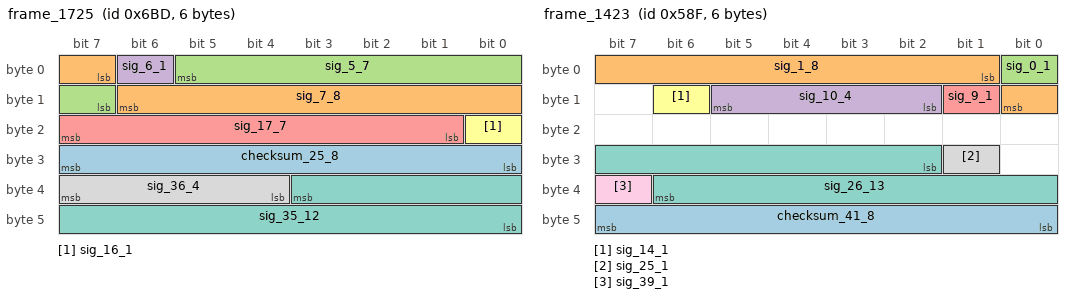
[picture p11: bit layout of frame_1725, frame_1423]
BO_ 1725 frame_1725: 6 ECU
  SG_ checksum_25_8 : 24|8@1+ (1.0,0.0) [0.0|255.0] "" Vector__XXX
  SG_ sig_7_8 : 7|8@1+ (1000.0,-31622.776601683792) [-31622.776601683792|222377.22339831622] "km/h" Vector__XXX
  SG_ sig_5_7 : 5|7@0+ (1.0000000000000005E-4,-0.0031622776601683794) [-0.0031622776601683794|0.009437722339831625] "A" Vector__XXX
  SG_ sig_6_1 : 6|1@0+ (1.0,0.0) [0.0|1.0] "" Vector__XXX
  SG_ sig_17_7 : 17|7@1+ (1.0000000000000007E-7,0.0) [0.0|1.260000000000001E-5] "s" Vector__XXX
  SG_ sig_16_1 : 16|1@0+ (1.0,0.0) [0.0|1.0] "" Vector__XXX
  SG_ sig_35_12 : 35|12@0- (10.0,0.0) [-20480.0|20460.0] "V" Vector__XXX
  SG_ sig_36_4 : 36|4@1- (100.0,-316.22776601683796) [-1116.227766016838|283.77223398316204] "A" Vector__XXX

BO_ 208 frame_208: 6 ECU
  SG_ checksum_9_8 : 8|8@1+ (1.0,0.0) [0.0|255.0] "" Vector__XXX
  SG_ sig_7_8 : 7|8@0- (0.010000000000000002,0.0) [-1.2800000000000002|1.2600000000000002] "s" Vector__XXX
  SG_ sig_24_13 : 24|13@1- (0.0010000000000000002,0.0) [-4.096000000000001|4.094000000000001] "W" Vector__XXX
  SG_ sig_39_2 : 39|2@0+ (1.0,0.0) [0.0|3.0] "" Vector__XXX
  SG_ sig_47_8 : 47|8@0- (100.0,0.0) [-12800.0|12600.0] "s" Vector__XXX

BO_ 1246 frame_1246: 5 Vector__XXX
  SG_ checksum_9_8 : 15|8@0+ (1.0,0.0) [0.0|255.0] "" ECU
  SG_ sig_7_8 : 7|8@0+ (0.0010000000000000002,0.03162277660168379) [0.03162277660168379|0.28562277660168384] "m/s^2" ECU
  SG_ sig_24_15 : 24|15@1- (1.0,0.0) [-16384.0|16382.0] "" ECU
  SG_ sig_22_5 : 22|5@0- (1.0,31.622776601683793) [15.622776601683793|45.622776601683796] "W" ECU
  SG_ sig_17_2 : 17|2@0- (1.0,0.0) [-2.0|1.0] "" ECU

BO_ 1423 frame_1423: 6 Vector__XXX
  SG_ checksum_41_8 : 40|8@1+ (1.0,0.0) [0.0|255.0] "" ECU
  SG_ sig_1_8 : 1|8@1+ (1.0,0.0) [0.0|254.0] "" ECU
  SG_ sig_0_1 : 0|1@1+ (1.0,0.0) [0.0|1.0] "" ECU
  SG_ sig_10_4 : 10|4@1- (1.0000000000000006E-6,3.162277660168379E-6) [-4.8377223398316255E-6|9.162277660168383E-6] "V" ECU
  SG_ sig_9_1 : 9|1@1+ (1.0,0.0) [0.0|1.0] "" ECU
  SG_ sig_14_1 : 14|1@1+ (1.0,0.0) [0.0|1.0] "" ECU
  SG_ sig_26_13 : 26|13@1- (10.0,31622.776601683792) [-9337.223398316208|72562.77660168378] "s" ECU
  SG_ sig_25_1 : 25|1@1+ (1.0,0.0) [0.0|1.0] "" ECU
  SG_ sig_39_1 : 39|1@1+ (1.0,0.0) [0.0|1.0] "" ECU

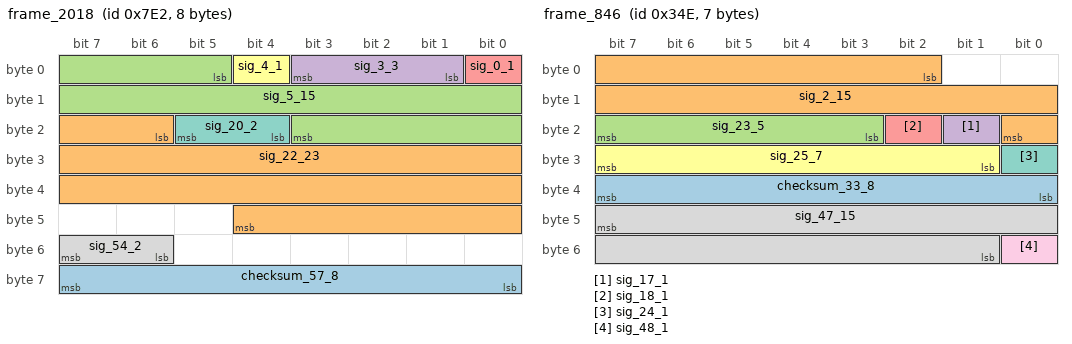
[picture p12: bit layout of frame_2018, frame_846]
BO_ 2018 frame_2018: 8 ECU
  SG_ checksum_57_8 : 56|8@1+ (1.0,0.0) [0.0|255.0] "" Vector__XXX
  SG_ sig_22_23 : 22|23@1- (1.0000000000000008E-8,-0.03162277660168379) [-0.07356581660168382|0.010320243398316241] "m/s^2" Vector__XXX
  SG_ sig_5_15 : 5|15@1- (1.0000000000000007E-7,0.0031622776601683794) [0.0015238776601683782|0.004800477660168381] "km/h" Vector__XXX
  SG_ sig_3_3 : 3|3@0- (1.0,0.0) [-4.0|2.0] "" Vector__XXX
  SG_ sig_0_1 : 0|1@1+ (1.0,0.0) [0.0|1.0] "" Vector__XXX
  SG_ sig_4_1 : 4|1@1+ (1.0,0.0) [0.0|1.0] "" Vector__XXX
  SG_ sig_20_2 : 20|2@1+ (1.0,0.0) [0.0|3.0] "" Vector__XXX
  SG_ sig_54_2 : 54|2@1+ (1.0,0.0) [0.0|3.0] "" Vector__XXX

BO_ 846 frame_846: 7 Vector__XXX
  SG_ checksum_33_8 : 32|8@1+ (1.0,0.0) [0.0|255.0] "" ECU
  SG_ sig_2_15 : 2|15@1+ (1.0,0.0) [0.0|32766.0] "" ECU
  SG_ sig_23_5 : 23|5@0- (0.0010000000000000002,0.03162277660168379) [0.015622776601683788|0.0456227766016838] "A" ECU
  SG_ sig_17_1 : 17|1@0+ (1.0,0.0) [0.0|1.0] "" ECU
  SG_ sig_18_1 : 18|1@0+ (1.0,0.0) [0.0|1.0] "" ECU
  SG_ sig_25_7 : 25|7@1+ (1.0,0.0) [0.0|126.0] "" ECU
  SG_ sig_24_1 : 24|1@1+ (1.0,0.0) [0.0|1.0] "" ECU
  SG_ sig_47_15 : 47|15@0- (1.0000000000000008E-8,-3.1622776601683794E-4) [-4.800677660168381E-4|-1.524077660168378E-4] "m/s^2" ECU
  SG_ sig_48_1 : 48|1@0+ (1.0,0.0) [0.0|1.0] "" ECU

BO_ 1764 frame_1764: 7 Vector__XXX
  SG_ checksum_33_8 : 39|8@0+ (1.0,0.0) [0.0|255.0] "" ECU
  SG_ sig_21_14 : 21|14@0- (1.0000000000000006E-6,-0.0031622776601683794) [-0.011354277660168385|0.005027722339831625] "kWh" ECU
  SG_ sig_7_16 : 7|16@0- (1.0,0.0) [-32768.0|32766.0] "" ECU
  SG_ sig_23_2 : 23|2@0+ (1.0,0.0) [0.0|3.0] "" ECU
  SG_ sig_47_13 : 47|13@0- (1.0,0.0) [-4096.0|4094.0] "" ECU
  SG_ sig_50_2 : 50|2@0+ (1.0,0.0) [0.0|3.0] "" ECU
  SG_ sig_48_1 : 48|1@0+ (1.0,0.0) [0.0|1.0] "" ECU

BO_ 1412 frame_1412: 5 Vector__XXX
  SG_ checksum_1_8 : 0|8@1+ (1.0,0.0) [0.0|255.0] "" ECU
  SG_ sig_10_8 : 10|8@1- (1.0000000000000006E-5,0.0) [-0.0012800000000000008|0.0012600000000000007] "A" ECU
  SG_ sig_8_2 : 8|2@1- (1.0,0.0) [-2.0|1.0] "" ECU
  SG_ sig_23_6 : 23|6@0+ (1.0000000000000006E-5,0.0) [0.0|6.200000000000003E-4] "s" ECU
  SG_ sig_27_8 : 27|8@1- (0.0010000000000000002,-0.03162277660168379) [-0.15962277660168384|0.09437722339831624] "kWh" ECU
  SG_ sig_25_2 : 25|2@1+ (1.0,0.0) [0.0|3.0] "" ECU
  SG_ sig_36_2 : 36|2@0- (1.0,0.0) [-2.0|1.0] "" ECU

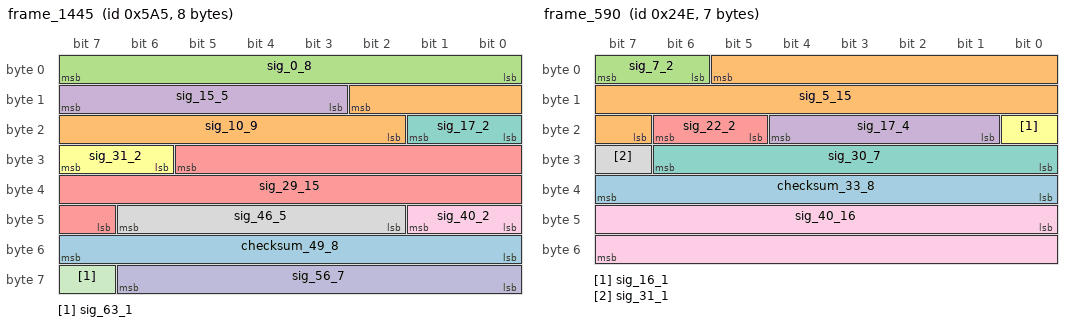
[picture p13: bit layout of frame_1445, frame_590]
BO_ 1445 frame_1445: 8 Vector__XXX
  SG_ checksum_49_8 : 48|8@1+ (1.0,0.0) [0.0|255.0] "" ECU
  SG_ sig_10_9 : 10|9@0+ (1.0,0.0) [0.0|510.0] "" ECU
  SG_ sig_0_8 : 0|8@1- (1.0000000000000007E-7,0.0) [-1.280000000000001E-5|1.260000000000001E-5] "s" ECU
  SG_ sig_15_5 : 15|5@0- (1000.0,0.0) [-16000.0|14000.0] "W" ECU
  SG_ sig_29_15 : 29|15@0- (1.0000000000000007E-7,0.0) [-0.0016384000000000012|0.0016382000000000013] "m/s^2" ECU
  SG_ sig_31_2 : 31|2@0+ (1.0,0.0) [0.0|3.0] "" ECU
  SG_ sig_17_2 : 17|2@0+ (1.0,0.0) [0.0|3.0] "" ECU
  SG_ sig_46_5 : 46|5@0+ (1.0,0.0) [0.0|30.0] "" ECU
  SG_ sig_40_2 : 40|2@1- (1.0,0.0) [-2.0|1.0] "" ECU
  SG_ sig_56_7 : 56|7@1+ (1000.0,-31622.776601683792) [-31622.776601683792|94377.22339831622] "km/h" ECU
  SG_ sig_63_1 : 63|1@1+ (1.0,0.0) [0.0|1.0] "" ECU

BO_ 590 frame_590: 7 ECU
  SG_ checksum_33_8 : 39|8@0+ (1.0,0.0) [0.0|255.0] "" Vector__XXX
  SG_ sig_5_15 : 5|15@0+ (1.0,0.0) [0.0|32766.0] "" Vector__XXX
  SG_ sig_7_2 : 7|2@0+ (1.0,0.0) [0.0|3.0] "" Vector__XXX
  SG_ sig_17_4 : 17|4@1- (1000.0,-3162.2776601683795) [-11162.27766016838|2837.7223398316205] "m/s^2" Vector__XXX
  SG_ sig_22_2 : 22|2@0+ (1.0,0.0) [0.0|3.0] "" Vector__XXX
  SG_ sig_16_1 : 16|1@1+ (1.0,0.0) [0.0|1.0] "" Vector__XXX
  SG_ sig_30_7 : 30|7@0- (100.0,-3162.2776601683795) [-9562.27766016838|3037.7223398316205] "A" Vector__XXX
  SG_ sig_31_1 : 31|1@0+ (1.0,0.0) [0.0|1.0] "" Vector__XXX
  SG_ sig_40_16 : 40|16@1- (0.1,3162.2776601683795) [-114.52233983162068|6438.87766016838] "m/s^2" Vector__XXX

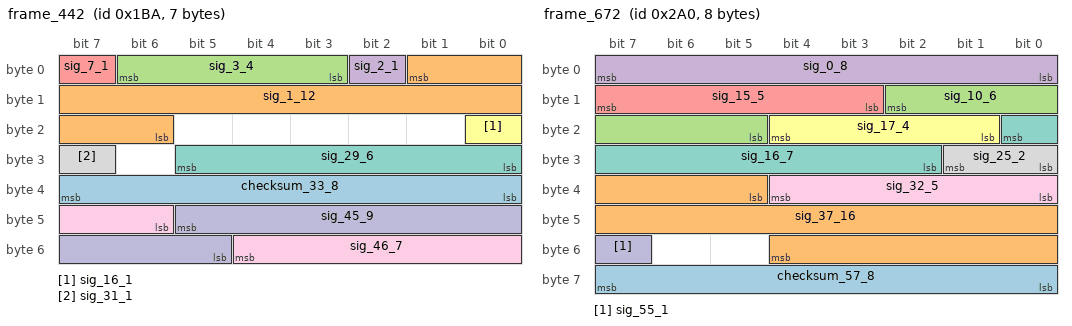
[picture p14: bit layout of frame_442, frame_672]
BO_ 442 frame_442: 7 Vector__XXX
  SG_ checksum_33_8 : 32|8@1+ (1.0,0.0) [0.0|255.0] "" ECU
  SG_ sig_1_12 : 1|12@0+ (1.0,0.0) [0.0|4094.0] "" ECU
  SG_ sig_3_4 : 3|4@1+ (1.0,0.0) [0.0|14.0] "" ECU
  SG_ sig_2_1 : 2|1@1+ (1.0,0.0) [0.0|1.0] "" ECU
  SG_ sig_7_1 : 7|1@1+ (1.0,0.0) [0.0|1.0] "" ECU
  SG_ sig_16_1 : 16|1@1+ (1.0,0.0) [0.0|1.0] "" ECU
  SG_ sig_29_6 : 29|6@0+ (100.0,0.0) [0.0|6200.0] "s" ECU
  SG_ sig_31_1 : 31|1@1+ (1.0,0.0) [0.0|1.0] "" ECU
  SG_ sig_46_7 : 46|7@1+ (0.1,3.1622776601683795) [3.1622776601683795|15.762277660168381] "W" ECU
  SG_ sig_45_9 : 45|9@0- (1.0,0.0) [-256.0|254.0] "" ECU

BO_ 672 frame_672: 8 Vector__XXX
  SG_ checksum_57_8 : 56|8@1+ (1.0,0.0) [0.0|255.0] "" ECU
  SG_ sig_37_16 : 37|16@1- (1.0,0.0) [-32768.0|32766.0] "" ECU
  SG_ sig_10_6 : 10|6@0- (10.0,316.22776601683796) [-3.772233983162039|616.2277660168379] "m/s^2" ECU
  SG_ sig_0_8 : 0|8@1- (0.1,-3.1622776601683795) [-15.96227766016838|9.437722339831621] "s" ECU
  SG_ sig_15_5 : 15|5@0+ (100.0,3162.2776601683795) [3162.2776601683795|6162.27766016838] "A" ECU
  SG_ sig_17_4 : 17|4@1- (1.0,0.0) [-8.0|6.0] "" ECU
  SG_ sig_16_7 : 16|7@0+ (1.0,0.0) [0.0|126.0] "" ECU
  SG_ sig_25_2 : 25|2@0- (1.0,0.0) [-2.0|1.0] "" ECU
  SG_ sig_32_5 : 32|5@1+ (1.0,0.0) [0.0|30.0] "" ECU
  SG_ sig_55_1 : 55|1@1+ (1.0,0.0) [0.0|1.0] "" ECU

BO_ 1419 frame_1419: 6 ECU
  SG_ checksum_25_8 : 31|8@0+ (1.0,0.0) [0.0|255.0] "" Vector__XXX
  SG_ sig_8_8 : 8|8@1+ (1.0,0.0) [0.0|254.0] "" Vector__XXX
  SG_ sig_0_7 : 0|7@1- (1.0,0.0) [-64.0|62.0] "" Vector__XXX
  SG_ sig_7_1 : 7|1@1+ (1.0,0.0) [0.0|1.0] "" Vector__XXX
  SG_ sig_23_7 : 23|7@0+ (1.0000000000000005E-4,0.0031622776601683794) [0.0031622776601683794|0.015762277660168383] "km/h" Vector__XXX
  SG_ sig_16_1 : 16|1@0+ (1.0,0.0) [0.0|1.0] "" Vector__XXX
  SG_ sig_32_4 : 32|4@1+ (1.0000000000000006E-6,0.0) [0.0|1.4000000000000008E-5] "V" Vector__XXX

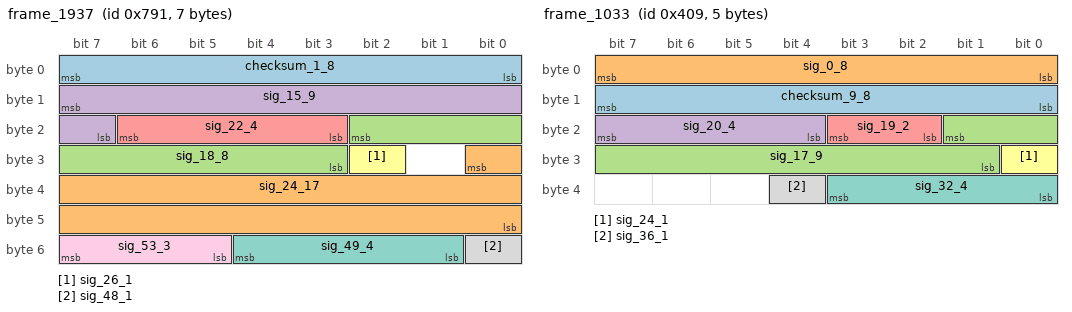
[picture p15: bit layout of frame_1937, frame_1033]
BO_ 1937 frame_1937: 7 ECU
  SG_ checksum_1_8 : 0|8@1+ (1.0,0.0) [0.0|255.0] "" Vector__XXX
  SG_ sig_24_17 : 24|17@0- (1.0000000000000006E-5,0.0) [-0.6553600000000004|0.6553400000000004] "A" Vector__XXX
  SG_ sig_18_8 : 18|8@0+ (1.0000000000000005E-4,0.0) [0.0|0.025400000000000013] "kWh" Vector__XXX
  SG_ sig_15_9 : 15|9@0+ (1.0,316.22776601683796) [316.22776601683796|826.2277660168379] "V" Vector__XXX
  SG_ sig_22_4 : 22|4@0+ (1.0,0.0) [0.0|14.0] "" Vector__XXX
  SG_ sig_26_1 : 26|1@0+ (1.0,0.0) [0.0|1.0] "" Vector__XXX
  SG_ sig_49_4 : 49|4@1- (1.0,0.0) [-8.0|6.0] "" Vector__XXX
  SG_ sig_48_1 : 48|1@1+ (1.0,0.0) [0.0|1.0] "" Vector__XXX
  SG_ sig_53_3 : 53|3@1- (1.0,0.0) [-4.0|2.0] "" Vector__XXX

BO_ 1630 frame_1630: 7 ECU
  SG_ checksum_49_8 : 48|8@1+ (1.0,0.0) [0.0|255.0] "" Vector__XXX
  SG_ sig_40_7 : 40|7@1+ (1.0,0.0) [0.0|126.0] "" Vector__XXX
  SG_ sig_6_15 : 6|15@0+ (0.010000000000000002,316.22776601683796) [316.22776601683796|643.887766016838] "s" Vector__XXX
  SG_ sig_7_1 : 7|1@1+ (1.0,0.0) [0.0|1.0] "" Vector__XXX
  SG_ sig_16_14 : 16|14@1- (1.0,0.0) [-8192.0|8190.0] "" Vector__XXX
  SG_ sig_47_1 : 47|1@0+ (1.0,0.0) [0.0|1.0] "" Vector__XXX

BO_ 718 frame_718: 7 Vector__XXX
  SG_ checksum_17_8 : 23|8@0+ (1.0,0.0) [0.0|255.0] "" ECU
  SG_ sig_7_10 : 7|10@0+ (0.1,-31.622776601683793) [-31.622776601683793|70.5772233983162] "s" ECU
  SG_ sig_10_4 : 10|4@1- (1.0,0.0) [-8.0|6.0] "" ECU
  SG_ sig_32_17 : 32|17@0+ (1.0,0.0) [0.0|131070.0] "" ECU
  SG_ sig_24_8 : 24|8@1+ (1.0,0.0) [0.0|254.0] "" ECU
  SG_ sig_33_6 : 33|6@1- (0.1,-3.1622776601683795) [-6.362277660168379|-0.16227766016837952] "A" ECU

BO_ 1042 frame_1042: 7 Vector__XXX
  SG_ checksum_1_8 : 0|8@1+ (1.0,0.0) [0.0|255.0] "" ECU
  SG_ sig_10_21 : 10|21@1+ (1.0000000000000007E-7,-0.03162277660168379) [-0.03162277660168379|0.17809222339831637] "m/s^2" ECU
  SG_ sig_8_2 : 8|2@1+ (1.0,0.0) [0.0|3.0] "" ECU
  SG_ sig_35_12 : 35|12@1- (1.0,0.0) [-2048.0|2046.0] "" ECU
  SG_ sig_33_2 : 33|2@1+ (1.0,0.0) [0.0|3.0] "" ECU
  SG_ sig_47_7 : 47|7@1+ (1.0000000000000006E-6,3.1622776601683795E-5) [3.1622776601683795E-5|1.5762277660168387E-4] "kWh" ECU
  SG_ sig_54_2 : 54|2@1- (1.0,0.0) [-2.0|1.0] "" ECU

BO_ 2013 frame_2013: 8 Vector__XXX
  SG_ checksum_33_8 : 39|8@0+ (1.0,0.0) [0.0|255.0] "" ECU
  SG_ sig_7_17 : 7|17@1+ (1.0000000000000008E-8,0.0) [0.0|0.001310700000000001] "V" ECU
  SG_ sig_0_7 : 0|7@1+ (0.1,-3.1622776601683795) [-3.1622776601683795|9.437722339831621] "A" ECU
  SG_ sig_24_8 : 24|8@1+ (10.0,316.22776601683796) [316.22776601683796|2856.227766016838] "kWh" ECU
  SG_ sig_40_15 : 40|15@1+ (1.0000000000000006E-5,0.0) [0.0|0.3276600000000002] "m/s^2" ECU
  SG_ sig_55_1 : 55|1@0+ (1.0,0.0) [0.0|1.0] "" ECU
  SG_ sig_56_8 : 56|8@1- (0.010000000000000002,0.0) [-1.2800000000000002|1.2600000000000002] "kWh" ECU

BO_ 1473 frame_1473: 7 Vector__XXX
  SG_ checksum_17_8 : 23|8@0+ (1.0,0.0) [0.0|255.0] "" ECU
  SG_ sig_3_9 : 3|9@0- (1.0000000000000007E-7,0.0) [-2.560000000000002E-5|2.5400000000000018E-5] "m/s^2" ECU
  SG_ sig_4_7 : 4|7@1+ (1.0,0.0) [0.0|126.0] "" ECU
  SG_ sig_24_16 : 24|16@1- (1.0000000000000005E-4,3.1622776601683795) [-0.11452233983162197|6.438877660168381] "s" ECU
  SG_ sig_47_16 : 47|16@0- (1.0000000000000009E-9,3.1622776601683795E-5) [-1.1452233983162338E-6|6.438877660168383E-5] "kWh" ECU

BO_ 1033 frame_1033: 5 ECU
  SG_ checksum_9_8 : 15|8@0+ (1.0,0.0) [0.0|255.0] "" Vector__XXX
  SG_ sig_0_8 : 0|8@1- (0.1,-3.1622776601683795) [-15.96227766016838|9.437722339831621] "V" Vector__XXX
  SG_ sig_17_9 : 17|9@0- (1.0,0.0) [-256.0|254.0] "" Vector__XXX
  SG_ sig_20_4 : 20|4@1- (0.0010000000000000002,0.0031622776601683794) [-0.004837722339831622|0.009162277660168382] "V" Vector__XXX
  SG_ sig_19_2 : 19|2@0- (1.0,0.0) [-2.0|1.0] "" Vector__XXX
  SG_ sig_24_1 : 24|1@1+ (1.0,0.0) [0.0|1.0] "" Vector__XXX
  SG_ sig_32_4 : 32|4@1+ (1.0,0.0) [0.0|14.0] "" Vector__XXX
  SG_ sig_36_1 : 36|1@1+ (1.0,0.0) [0.0|1.0] "" Vector__XXX

BO_ 803 frame_803: 4 ECU
  SG_ checksum_17_8 : 16|8@1+ (1.0,0.0) [0.0|255.0] "" Vector__XXX
  SG_ sig_1_10 : 1|10@1+ (1.0,316.22776601683796) [316.22776601683796|1338.227766016838] "km/h" Vector__XXX
  SG_ sig_0_6 : 0|6@0- (0.0010000000000000002,0.03162277660168379) [-3.7722339831621626E-4|0.0616227766016838] "kWh" Vector__XXX
  SG_ sig_24_8 : 24|8@1- (1.0,0.0) [-128.0|126.0] "" Vector__XXX

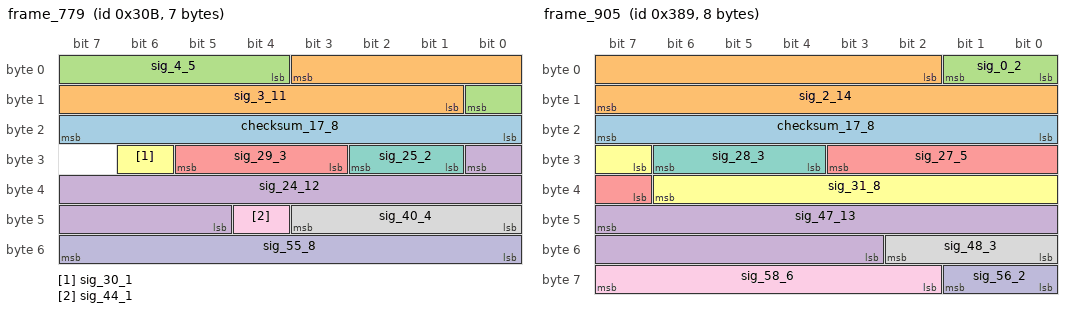
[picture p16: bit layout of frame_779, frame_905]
BO_ 779 frame_779: 7 Vector__XXX
  SG_ checksum_17_8 : 23|8@0+ (1.0,0.0) [0.0|255.0] "" ECU
  SG_ sig_3_11 : 3|11@0- (0.0010000000000000002,-0.31622776601683794) [-1.3402277660168382|0.7057722339831622] "s" ECU
  SG_ sig_4_5 : 4|5@1- (1.0000000000000007E-7,-3.162277660168379E-6) [-4.762277660168381E-6|-1.7622776601683782E-6] "kWh" ECU
  SG_ sig_24_12 : 24|12@0+ (1.0,0.0) [0.0|4094.0] "" ECU
  SG_ sig_29_3 : 29|3@0+ (1.0,0.0) [0.0|6.0] "" ECU
  SG_ sig_30_1 : 30|1@0+ (1.0,0.0) [0.0|1.0] "" ECU
  SG_ sig_25_2 : 25|2@1+ (1.0,0.0) [0.0|3.0] "" ECU
  SG_ sig_40_4 : 40|4@1+ (100.0,0.0) [0.0|1400.0] "m/s^2" ECU
  SG_ sig_44_1 : 44|1@1+ (1.0,0.0) [0.0|1.0] "" ECU
  SG_ sig_55_8 : 55|8@0+ (100.0,-3162.2776601683795) [-3162.2776601683795|22237.72233983162] "A" ECU

BO_ 106 frame_106: 5 ECU
  SG_ checksum_17_8 : 16|8@1+ (1.0,0.0) [0.0|255.0] "" Vector__XXX
  SG_ sig_7_11 : 7|11@0+ (0.1,31.622776601683793) [31.622776601683793|236.22277660168382] "A" Vector__XXX
  SG_ sig_8_5 : 8|5@1- (1.0000000000000005E-4,0.0) [-0.0016000000000000007|0.0014000000000000006] "W" Vector__XXX
  SG_ sig_29_14 : 29|14@0+ (10.0,-31622.776601683792) [-31622.776601683792|132197.22339831622] "W" Vector__XXX
  SG_ sig_30_2 : 30|2@1- (1.0,0.0) [-2.0|1.0] "" Vector__XXX

BO_ 905 frame_905: 8 ECU
  SG_ checksum_17_8 : 16|8@1+ (1.0,0.0) [0.0|255.0] "" Vector__XXX
  SG_ sig_2_14 : 2|14@1+ (1.0000000000000008E-8,-3.1622776601683795E-5) [-3.1622776601683795E-5|1.3219722339831636E-4] "s" Vector__XXX
  SG_ sig_0_2 : 0|2@1+ (1.0,0.0) [0.0|3.0] "" Vector__XXX
  SG_ sig_47_13 : 47|13@0- (1.0,3162.2776601683795) [-933.7223398316205|7256.27766016838] "A" Vector__XXX
  SG_ sig_27_5 : 27|5@0+ (1.0,0.0) [0.0|30.0] "" Vector__XXX
  SG_ sig_31_8 : 31|8@1+ (1.0,0.0) [0.0|254.0] "" Vector__XXX
  SG_ sig_28_3 : 28|3@1+ (1.0,0.0) [0.0|6.0] "" Vector__XXX
  SG_ sig_48_3 : 48|3@1+ (1.0,0.0) [0.0|6.0] "" Vector__XXX
  SG_ sig_58_6 : 58|6@1- (0.010000000000000002,0.0) [-0.32000000000000006|0.30000000000000004] "W" Vector__XXX
  SG_ sig_56_2 : 56|2@1+ (1.0,0.0) [0.0|3.0] "" Vector__XXX

BO_ 877 frame_877: 4 Vector__XXX
  SG_ checksum_9_8 : 8|8@1+ (1.0,0.0) [0.0|255.0] "" ECU
  SG_ sig_7_7 : 7|7@0- (100.0,3162.2776601683795) [-3237.7223398316205|9362.27766016838] "kWh" ECU
  SG_ sig_0_1 : 0|1@0+ (1.0,0.0) [0.0|1.0] "" ECU
  SG_ sig_20_7 : 20|7@0+ (1.0000000000000006E-6,3.1622776601683795E-5) [3.1622776601683795E-5|1.5762277660168387E-4] "A" ECU
  SG_ sig_21_9 : 21|9@1- (0.1,0.0) [-25.6|25.400000000000002] "m/s^2" ECU

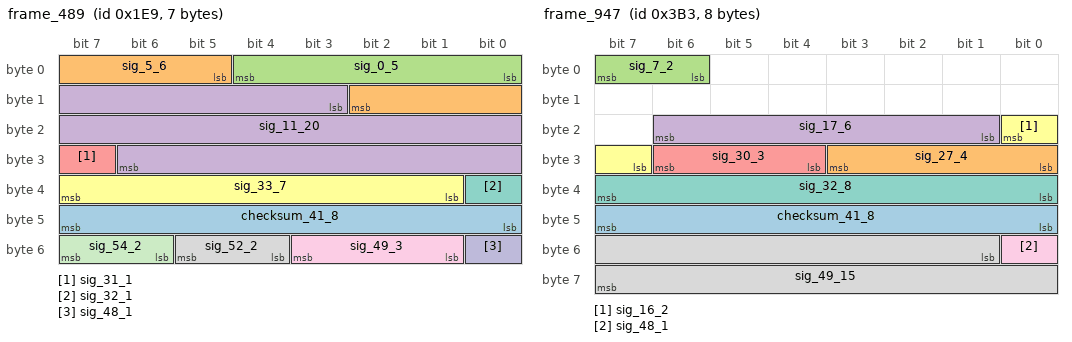
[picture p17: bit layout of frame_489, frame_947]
BO_ 489 frame_489: 7 Vector__XXX
  SG_ checksum_41_8 : 40|8@1+ (1.0,0.0) [0.0|255.0] "" ECU
  SG_ sig_5_6 : 5|6@1- (1.0000000000000006E-6,0.0) [-3.200000000000002E-5|3.0000000000000018E-5] "kWh" ECU
  SG_ sig_0_5 : 0|5@1- (1.0000000000000005E-4,0.0) [-0.0016000000000000007|0.0014000000000000006] "V" ECU
  SG_ sig_11_20 : 11|20@1+ (0.1,31622.776601683792) [31622.776601683792|136480.1766016838] "m/s^2" ECU
  SG_ sig_31_1 : 31|1@0+ (1.0,0.0) [0.0|1.0] "" ECU
  SG_ sig_33_7 : 33|7@1- (1000.0,31622.776601683792) [-32377.223398316208|93622.77660168378] "A" ECU
  SG_ sig_32_1 : 32|1@1+ (1.0,0.0) [0.0|1.0] "" ECU
  SG_ sig_52_2 : 52|2@1- (1.0,0.0) [-2.0|1.0] "" ECU
  SG_ sig_49_3 : 49|3@1+ (1.0,0.0) [0.0|6.0] "" ECU
  SG_ sig_48_1 : 48|1@1+ (1.0,0.0) [0.0|1.0] "" ECU
  SG_ sig_54_2 : 54|2@1+ (1.0,0.0) [0.0|3.0] "" ECU

BO_ 1758 frame_1758: 5 Vector__XXX
  SG_ checksum_25_8 : 24|8@1+ (1.0,0.0) [0.0|255.0] "" ECU
  SG_ sig_6_16 : 6|16@0- (1.0,0.0) [-32768.0|32766.0] "" ECU
  SG_ sig_7_1 : 7|1@0+ (1.0,0.0) [0.0|1.0] "" ECU
  SG_ sig_16_7 : 16|7@1- (1000.0,-31622.776601683792) [-95622.77660168378|30377.223398316208] "W" ECU
  SG_ sig_39_8 : 39|8@0- (1.0,31.622776601683793) [-96.3772233983162|157.6227766016838] "V" ECU

BO_ 1998 frame_1998: 7 ECU
  SG_ checksum_1_8 : 0|8@1+ (1.0,0.0) [0.0|255.0] "" Vector__XXX
  SG_ sig_11_13 : 11|13@1+ (1.0000000000000007E-7,-3.1622776601683794E-4) [-3.1622776601683794E-4|5.027722339831627E-4] "W" Vector__XXX
  SG_ sig_9_2 : 9|2@1+ (1.0,0.0) [0.0|3.0] "" Vector__XXX
  SG_ sig_8_1 : 8|1@0+ (1.0,0.0) [0.0|1.0] "" Vector__XXX
  SG_ sig_30_24 : 30|24@0+ (1.000000000000001E-11,3.1622776601683795E-5) [3.1622776601683795E-5|1.9939491660168397E-4] "m/s^2" Vector__XXX
  SG_ sig_31_1 : 31|1@1+ (1.0,0.0) [0.0|1.0] "" Vector__XXX
  SG_ sig_54_7 : 54|7@0- (1.0,-31.622776601683793) [-95.6227766016838|30.377223398316207] "km/h" Vector__XXX

BO_ 1324 frame_1324: 2 Vector__XXX
  SG_ checksum_9_8 : 15|8@0+ (1.0,0.0) [0.0|255.0] "" ECU
  SG_ sig_7_5 : 7|5@0- (0.0010000000000000002,0.0) [-0.016000000000000004|0.014000000000000004] "km/h" ECU
  SG_ sig_2_3 : 2|3@0- (1.0,0.0) [-4.0|2.0] "" ECU

BO_ 1885 frame_1885: 4 ECU
  SG_ checksum_1_8 : 7|8@0+ (1.0,0.0) [0.0|255.0] "" Vector__XXX
  SG_ sig_13_13 : 13|13@0- (1.0,0.0) [-4096.0|4094.0] "" Vector__XXX
  SG_ sig_15_2 : 15|2@0- (1.0,0.0) [-2.0|1.0] "" Vector__XXX
  SG_ sig_31_8 : 31|8@0+ (1.0,0.0) [0.0|254.0] "" Vector__XXX
  SG_ sig_16_1 : 16|1@0+ (1.0,0.0) [0.0|1.0] "" Vector__XXX

BO_ 1415 frame_1415: 5 ECU
  SG_ checksum_33_8 : 32|8@1+ (1.0,0.0) [0.0|255.0] "" Vector__XXX
  SG_ sig_9_12 : 9|12@0- (1.0,0.0) [-2048.0|2046.0] "" Vector__XXX
  SG_ sig_0_4 : 0|4@1+ (1000.0,0.0) [0.0|14000.0] "s" Vector__XXX
  SG_ sig_11_5 : 11|5@1- (1.0000000000000006E-5,-3.1622776601683794E-4) [-4.7622776601683803E-4|-1.7622776601683784E-4] "A" Vector__XXX
  SG_ sig_10_1 : 10|1@0+ (1.0,0.0) [0.0|1.0] "" Vector__XXX
  SG_ sig_29_5 : 29|5@0+ (100.0,3162.2776601683795) [3162.2776601683795|6162.27766016838] "W" Vector__XXX
  SG_ sig_24_1 : 24|1@0+ (1.0,0.0) [0.0|1.0] "" Vector__XXX

BO_ 1252 frame_1252: 5 Vector__XXX
  SG_ checksum_25_8 : 31|8@0+ (1.0,0.0) [0.0|255.0] "" ECU
  SG_ sig_2_17 : 2|17@1- (1.0,31622.776601683792) [-33913.22339831621|97156.77660168378] "m/s^2" ECU
  SG_ sig_0_2 : 0|2@1- (1.0,0.0) [-2.0|1.0] "" ECU
  SG_ sig_23_5 : 23|5@0- (1.0,0.0) [-16.0|14.0] "" ECU
  SG_ sig_39_7 : 39|7@0+ (0.0010000000000000002,0.03162277660168379) [0.03162277660168379|0.15762277660168383] "m/s^2" ECU
  SG_ sig_32_1 : 32|1@0+ (1.0,0.0) [0.0|1.0] "" ECU

BO_ 947 frame_947: 8 Vector__XXX
  SG_ checksum_41_8 : 47|8@0+ (1.0,0.0) [0.0|255.0] "" ECU
  SG_ sig_27_4 : 27|4@0+ (0.1,-0.31622776601683794) [-0.31622776601683794|1.0837722339831621] "s" ECU
  SG_ sig_7_2 : 7|2@0- (1.0,0.0) [-2.0|1.0] "" ECU
  SG_ sig_17_6 : 17|6@1+ (1.0000000000000005E-4,0.0031622776601683794) [0.0031622776601683794|0.009362277660168382] "km/h" ECU
  SG_ sig_30_3 : 30|3@0+ (1.0,0.0) [0.0|6.0] "" ECU
  SG_ sig_16_2 : 16|2@0- (1.0,0.0) [-2.0|1.0] "" ECU
  SG_ sig_32_8 : 32|8@1+ (1.0,0.0) [0.0|254.0] "" ECU
  SG_ sig_49_15 : 49|15@1+ (1.0,0.0) [0.0|32766.0] "" ECU
  SG_ sig_48_1 : 48|1@0+ (1.0,0.0) [0.0|1.0] "" ECU

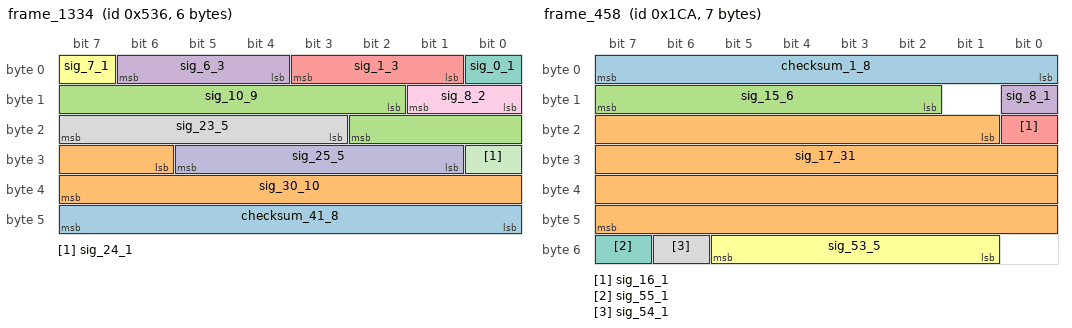
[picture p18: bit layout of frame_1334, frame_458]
BO_ 1334 frame_1334: 6 Vector__XXX
  SG_ checksum_41_8 : 47|8@0+ (1.0,0.0) [0.0|255.0] "" ECU
  SG_ sig_30_10 : 30|10@1+ (1.0,316.22776601683796) [316.22776601683796|1338.227766016838] "V" ECU
  SG_ sig_10_9 : 10|9@1+ (1.0,0.0) [0.0|510.0] "" ECU
  SG_ sig_6_3 : 6|3@0+ (1.0,0.0) [0.0|6.0] "" ECU
  SG_ sig_1_3 : 1|3@1- (1.0,0.0) [-4.0|2.0] "" ECU
  SG_ sig_7_1 : 7|1@0+ (1.0,0.0) [0.0|1.0] "" ECU
  SG_ sig_0_1 : 0|1@1+ (1.0,0.0) [0.0|1.0] "" ECU
  SG_ sig_23_5 : 23|5@0- (1.0,0.0) [-16.0|14.0] "" ECU
  SG_ sig_8_2 : 8|2@1+ (1.0,0.0) [0.0|3.0] "" ECU
  SG_ sig_25_5 : 25|5@1+ (10.0,0.0) [0.0|300.0] "s" ECU
  SG_ sig_24_1 : 24|1@0+ (1.0,0.0) [0.0|1.0] "" ECU

BO_ 458 frame_458: 7 Vector__XXX
  SG_ checksum_1_8 : 0|8@1+ (1.0,0.0) [0.0|255.0] "" ECU
  SG_ sig_17_31 : 17|31@1+ (1.0000000000000005E-4,31622.776601683792) [31622.776601683792|246371.14120168387] "s" ECU
  SG_ sig_15_6 : 15|6@0- (100.0,3162.2776601683795) [-37.7223398316205|6162.27766016838] "kWh" ECU
  SG_ sig_8_1 : 8|1@0+ (1.0,0.0) [0.0|1.0] "" ECU
  SG_ sig_16_1 : 16|1@1+ (1.0,0.0) [0.0|1.0] "" ECU
  SG_ sig_53_5 : 53|5@0+ (1.0000000000000005E-4,0.0031622776601683794) [0.0031622776601683794|0.006162277660168381] "V" ECU
  SG_ sig_55_1 : 55|1@0+ (1.0,0.0) [0.0|1.0] "" ECU
  SG_ sig_54_1 : 54|1@0+ (1.0,0.0) [0.0|1.0] "" ECU

BO_ 915 frame_915: 6 ECU
  SG_ checksum_25_8 : 31|8@0+ (1.0,0.0) [0.0|255.0] "" Vector__XXX
  SG_ sig_1_12 : 1|12@1- (1.0000000000000006E-6,0.0031622776601683794) [0.0011142776601683782|0.005208277660168381] "s" Vector__XXX
  SG_ sig_0_1 : 0|1@1+ (1.0,0.0) [0.0|1.0] "" Vector__XXX
  SG_ sig_36_13 : 36|13@0+ (1.0000000000000008E-8,3.1622776601683795E-5) [3.1622776601683795E-5|1.1352277660168385E-4] "A" Vector__XXX
  SG_ sig_39_2 : 39|2@0- (1.0,0.0) [-2.0|1.0] "" Vector__XXX
  SG_ sig_37_1 : 37|1@0+ (1.0,0.0) [0.0|1.0] "" Vector__XXX

BO_ 349 frame_349: 6 ECU
  SG_ checksum_17_8 : 23|8@0+ (1.0,0.0) [0.0|255.0] "" Vector__XXX
  SG_ sig_3_13 : 3|13@1- (1.0000000000000009E-9,-3.162277660168379E-6) [-7.258277660168383E-6|9.317223398316243E-7] "kWh" Vector__XXX
  SG_ sig_2_3 : 2|3@0- (1.0,0.0) [-4.0|2.0] "" Vector__XXX
  SG_ sig_28_10 : 28|10@0- (1.0000000000000006E-6,-3.1622776601683794E-4) [-8.282277660168382E-4|1.9377223398316231E-4] "kWh" Vector__XXX
  SG_ sig_46_7 : 46|7@0- (1.0,0.0) [-64.0|62.0] "" Vector__XXX
  SG_ sig_47_1 : 47|1@0+ (1.0,0.0) [0.0|1.0] "" Vector__XXX

BO_ 1 frame_1: 3 Vector__XXX
  SG_ checksum_1_8 : 7|8@0+ (1.0,0.0) [0.0|255.0] "" ECU
  SG_ sig_13_13 : 13|13@0+ (1.0,-3162.2776601683795) [-3162.2776601683795|5027.72233983162] "V" ECU
  SG_ sig_15_2 : 15|2@0+ (1.0,0.0) [0.0|3.0] "" ECU
  SG_ sig_16_1 : 16|1@1+ (1.0,0.0) [0.0|1.0] "" ECU

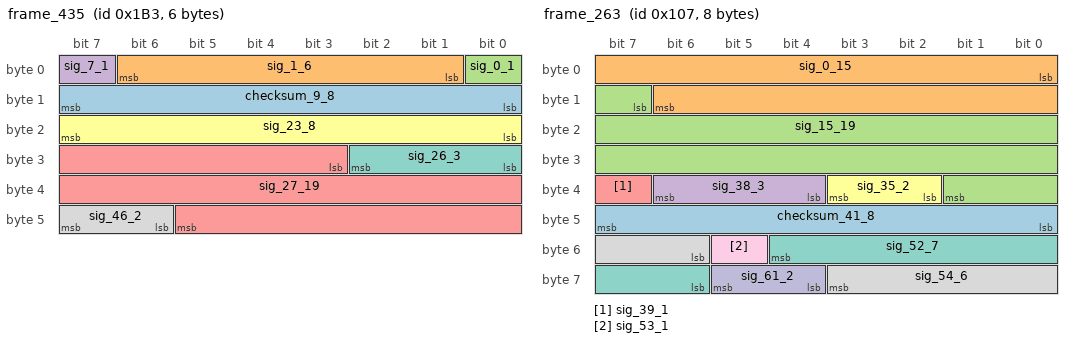
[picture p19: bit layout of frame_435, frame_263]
BO_ 435 frame_435: 6 Vector__XXX
  SG_ checksum_9_8 : 8|8@1+ (1.0,0.0) [0.0|255.0] "" ECU
  SG_ sig_1_6 : 1|6@1- (100.0,-3162.2776601683795) [-6362.27766016838|-162.2776601683795] "km/h" ECU
  SG_ sig_0_1 : 0|1@1+ (1.0,0.0) [0.0|1.0] "" ECU
  SG_ sig_7_1 : 7|1@0+ (1.0,0.0) [0.0|1.0] "" ECU
  SG_ sig_27_19 : 27|19@1- (1.000000000000001E-11,0.0) [-2.621440000000003E-6|2.6214200000000027E-6] "km/h" ECU
  SG_ sig_23_8 : 23|8@0+ (100.0,0.0) [0.0|25400.0] "A" ECU
  SG_ sig_26_3 : 26|3@0+ (1.0,0.0) [0.0|6.0] "" ECU
  SG_ sig_46_2 : 46|2@1- (1.0,0.0) [-2.0|1.0] "" ECU

BO_ 982 frame_982: 7 Vector__XXX
  SG_ checksum_1_8 : 7|8@0+ (1.0,0.0) [0.0|255.0] "" ECU
  SG_ sig_13_23 : 13|23@0- (1.000000000000001E-11,3.1622776601683795E-5) [-1.032026339831625E-5|7.356579660168383E-5] "s" ECU
  SG_ sig_15_2 : 15|2@0+ (1.0,0.0) [0.0|3.0] "" ECU
  SG_ sig_37_18 : 37|18@0- (1.0,0.0) [-131072.0|131070.0] "" ECU
  SG_ sig_38_1 : 38|1@0+ (1.0,0.0) [0.0|1.0] "" ECU
  SG_ sig_51_3 : 51|3@0- (1.0,0.0) [-4.0|2.0] "" ECU
  SG_ sig_48_1 : 48|1@0+ (1.0,0.0) [0.0|1.0] "" ECU

BO_ 263 frame_263: 8 Vector__XXX
  SG_ checksum_41_8 : 40|8@1+ (1.0,0.0) [0.0|255.0] "" ECU
  SG_ sig_0_15 : 0|15@1+ (1.0,0.0) [0.0|32766.0] "" ECU
  SG_ sig_15_19 : 15|19@1+ (1.0000000000000011E-10,0.0) [0.0|5.2428600000000056E-5] "W" ECU
  SG_ sig_38_3 : 38|3@0+ (1.0,0.0) [0.0|6.0] "" ECU
  SG_ sig_39_1 : 39|1@0+ (1.0,0.0) [0.0|1.0] "" ECU
  SG_ sig_35_2 : 35|2@0+ (1.0,0.0) [0.0|3.0] "" ECU
  SG_ sig_52_7 : 52|7@0- (10.0,0.0) [-640.0|620.0] "A" ECU
  SG_ sig_54_6 : 54|6@1+ (1.0000000000000006E-6,3.1622776601683795E-5) [3.1622776601683795E-5|9.362277660168383E-5] "m/s^2" ECU
  SG_ sig_53_1 : 53|1@1+ (1.0,0.0) [0.0|1.0] "" ECU
  SG_ sig_61_2 : 61|2@0- (1.0,0.0) [-2.0|1.0] "" ECU

CM_ BO_ 1706 "Randomly defined CAN frame";
CM_ SG_ 1706 checksum_57_8 "8 Bit checksum for protection of frame contents";
CM_ BO_ 1242 "Randomly defined CAN frame";
CM_ SG_ 1242 checksum_33_8 "8 Bit checksum for protection of frame contents";
CM_ BO_ 774 "Randomly defined CAN frame";
CM_ SG_ 774 checksum_1_8 "8 Bit checksum for protection of frame contents";
CM_ BO_ 2044 "Randomly defined CAN frame";
CM_ SG_ 2044 checksum_17_8 "8 Bit checksum for protection of frame contents";
CM_ BO_ 1907 "Randomly defined CAN frame";
CM_ SG_ 1907 checksum_1_8 "8 Bit checksum for protection of frame contents";
CM_ BO_ 594 "Randomly defined CAN frame";
CM_ SG_ 594 checksum_33_8 "8 Bit checksum for protection of frame contents";
CM_ BO_ 1049 "Randomly defined CAN frame";
CM_ SG_ 1049 checksum_49_8 "8 Bit checksum for protection of frame contents";
CM_ BO_ 1207 "Randomly defined CAN frame";
CM_ SG_ 1207 checksum_1_8 "8 Bit checksum for protection of frame contents";
CM_ BO_ 902 "Randomly defined CAN frame";
CM_ SG_ 902 checksum_33_8 "8 Bit checksum for protection of frame contents";
CM_ BO_ 1834 "Randomly defined CAN frame";
CM_ SG_ 1834 checksum_17_8 "8 Bit checksum for protection of frame contents";
CM_ BO_ 609 "Randomly defined CAN frame";
CM_ SG_ 609 checksum_1_8 "8 Bit checksum for protection of frame contents";
CM_ BO_ 1367 "Randomly defined CAN frame";
CM_ SG_ 1367 checksum_41_8 "8 Bit checksum for protection of frame contents";
CM_ BO_ 1053 "Randomly defined CAN frame";
CM_ SG_ 1053 checksum_25_8 "8 Bit checksum for protection of frame contents";
CM_ BO_ 1114 "Randomly defined CAN frame";
CM_ SG_ 1114 checksum_33_8 "8 Bit checksum for protection of frame contents";
CM_ BO_ 693 "Randomly defined CAN frame";
CM_ SG_ 693 checksum_41_8 "8 Bit checksum for protection of frame contents";
CM_ BO_ 1143 "Randomly defined CAN frame";
CM_ SG_ 1143 checksum_1_8 "8 Bit checksum for protection of frame contents";
CM_ BO_ 667 "Randomly defined CAN frame";
CM_ SG_ 667 checksum_1_8 "8 Bit checksum for protection of frame contents";
CM_ BO_ 453 "Randomly defined CAN frame";
CM_ SG_ 453 checksum_1_8 "8 Bit checksum for protection of frame contents";
CM_ BO_ 1294 "Randomly defined CAN frame";
CM_ SG_ 1294 checksum_17_8 "8 Bit checksum for protection of frame contents";
CM_ BO_ 403 "Randomly defined CAN frame";
CM_ SG_ 403 checksum_41_8 "8 Bit checksum for protection of frame contents";
CM_ BO_ 1051 "Randomly defined CAN frame";
CM_ SG_ 1051 checksum_17_8 "8 Bit checksum for protection of frame contents";
CM_ BO_ 1352 "Randomly defined CAN frame";
CM_ SG_ 1352 checksum_49_8 "8 Bit checksum for protection of frame contents";
CM_ BO_ 1140 "Randomly defined CAN frame";
CM_ SG_ 1140 checksum_33_8 "8 Bit checksum for protection of frame contents";
CM_ BO_ 652 "Randomly defined CAN frame";
CM_ SG_ 652 checksum_1_8 "8 Bit checksum for protection of frame contents";
CM_ BO_ 1091 "Randomly defined CAN frame";
CM_ SG_ 1091 checksum_49_8 "8 Bit checksum for protection of frame contents";
CM_ BO_ 1715 "Randomly defined CAN frame";
CM_ SG_ 1715 checksum_25_8 "8 Bit checksum for protection of frame contents";
CM_ BO_ 766 "Randomly defined CAN frame";
CM_ SG_ 766 checksum_9_8 "8 Bit checksum for protection of frame contents";
CM_ BO_ 131 "Randomly defined CAN frame";
CM_ SG_ 131 checksum_41_8 "8 Bit checksum for protection of frame contents";
CM_ BO_ 1271 "Randomly defined CAN frame";
CM_ SG_ 1271 checksum_41_8 "8 Bit checksum for protection of frame contents";
CM_ BO_ 332 "Randomly defined CAN frame";
CM_ SG_ 332 checksum_17_8 "8 Bit checksum for protection of frame contents";
CM_ BO_ 602 "Randomly defined CAN frame";
CM_ SG_ 602 checksum_1_8 "8 Bit checksum for protection of frame contents";
CM_ BO_ 833 "Randomly defined CAN frame";
CM_ SG_ 833 checksum_41_8 "8 Bit checksum for protection of frame contents";
CM_ BO_ 1605 "Randomly defined CAN frame";
CM_ SG_ 1605 checksum_25_8 "8 Bit checksum for protection of frame contents";
CM_ BO_ 514 "Randomly defined CAN frame";
CM_ SG_ 514 checksum_1_8 "8 Bit checksum for protection of frame contents";
CM_ BO_ 1731 "Randomly defined CAN frame";
CM_ SG_ 1731 checksum_9_8 "8 Bit checksum for protection of frame contents";
CM_ BO_ 1529 "Randomly defined CAN frame";
CM_ SG_ 1529 checksum_9_8 "8 Bit checksum for protection of frame contents";
CM_ BO_ 417 "Randomly defined CAN frame";
CM_ SG_ 417 checksum_9_8 "8 Bit checksum for protection of frame contents";
CM_ BO_ 808 "Randomly defined CAN frame";
CM_ SG_ 808 checksum_17_8 "8 Bit checksum for protection of frame contents";
CM_ BO_ 1181 "Randomly defined CAN frame";
CM_ SG_ 1181 checksum_1_8 "8 Bit checksum for protection of frame contents";
CM_ BO_ 1725 "Randomly defined CAN frame";
CM_ SG_ 1725 checksum_25_8 "8 Bit checksum for protection of frame contents";
CM_ BO_ 208 "Randomly defined CAN frame";
CM_ SG_ 208 checksum_9_8 "8 Bit checksum for protection of frame contents";
CM_ BO_ 1246 "Randomly defined CAN frame";
CM_ SG_ 1246 checksum_9_8 "8 Bit checksum for protection of frame contents";
CM_ BO_ 1423 "Randomly defined CAN frame";
CM_ SG_ 1423 checksum_41_8 "8 Bit checksum for protection of frame contents";
CM_ BO_ 2018 "Randomly defined CAN frame";
CM_ SG_ 2018 checksum_57_8 "8 Bit checksum for protection of frame contents";
CM_ BO_ 846 "Randomly defined CAN frame";
CM_ SG_ 846 checksum_33_8 "8 Bit checksum for protection of frame contents";
CM_ BO_ 1764 "Randomly defined CAN frame";
CM_ SG_ 1764 checksum_33_8 "8 Bit checksum for protection of frame contents";
CM_ BO_ 1412 "Randomly defined CAN frame";
CM_ SG_ 1412 checksum_1_8 "8 Bit checksum for protection of frame contents";
CM_ BO_ 1445 "Randomly defined CAN frame";
CM_ SG_ 1445 checksum_49_8 "8 Bit checksum for protection of frame contents";
CM_ BO_ 590 "Randomly defined CAN frame";
CM_ SG_ 590 checksum_33_8 "8 Bit checksum for protection of frame contents";
CM_ BO_ 442 "Randomly defined CAN frame";
CM_ SG_ 442 checksum_33_8 "8 Bit checksum for protection of frame contents";
CM_ BO_ 672 "Randomly defined CAN frame";
CM_ SG_ 672 checksum_57_8 "8 Bit checksum for protection of frame contents";
CM_ BO_ 1419 "Randomly defined CAN frame";
CM_ SG_ 1419 checksum_25_8 "8 Bit checksum for protection of frame contents";
CM_ BO_ 1937 "Randomly defined CAN frame";
CM_ SG_ 1937 checksum_1_8 "8 Bit checksum for protection of frame contents";
CM_ BO_ 1630 "Randomly defined CAN frame";
CM_ SG_ 1630 checksum_49_8 "8 Bit checksum for protection of frame contents";
CM_ BO_ 718 "Randomly defined CAN frame";
CM_ SG_ 718 checksum_17_8 "8 Bit checksum for protection of frame contents";
CM_ BO_ 1042 "Randomly defined CAN frame";
CM_ SG_ 1042 checksum_1_8 "8 Bit checksum for protection of frame contents";
CM_ BO_ 2013 "Randomly defined CAN frame";
CM_ SG_ 2013 checksum_33_8 "8 Bit checksum for protection of frame contents";
CM_ BO_ 1473 "Randomly defined CAN frame";
CM_ SG_ 1473 checksum_17_8 "8 Bit checksum for protection of frame contents";
CM_ BO_ 1033 "Randomly defined CAN frame";
CM_ SG_ 1033 checksum_9_8 "8 Bit checksum for protection of frame contents";
CM_ BO_ 803 "Randomly defined CAN frame";
CM_ SG_ 803 checksum_17_8 "8 Bit checksum for protection of frame contents";
CM_ BO_ 779 "Randomly defined CAN frame";
CM_ SG_ 779 checksum_17_8 "8 Bit checksum for protection of frame contents";
CM_ BO_ 106 "Randomly defined CAN frame";
CM_ SG_ 106 checksum_17_8 "8 Bit checksum for protection of frame contents";
CM_ BO_ 905 "Randomly defined CAN frame";
CM_ SG_ 905 checksum_17_8 "8 Bit checksum for protection of frame contents";
CM_ BO_ 877 "Randomly defined CAN frame";
CM_ SG_ 877 checksum_9_8 "8 Bit checksum for protection of frame contents";
CM_ BO_ 489 "Randomly defined CAN frame";
CM_ SG_ 489 checksum_41_8 "8 Bit checksum for protection of frame contents";
CM_ BO_ 1758 "Randomly defined CAN frame";
CM_ SG_ 1758 checksum_25_8 "8 Bit checksum for protection of frame contents";
CM_ BO_ 1998 "Randomly defined CAN frame";
CM_ SG_ 1998 checksum_1_8 "8 Bit checksum for protection of frame contents";
CM_ BO_ 1324 "Randomly defined CAN frame";
CM_ SG_ 1324 checksum_9_8 "8 Bit checksum for protection of frame contents";
CM_ BO_ 1885 "Randomly defined CAN frame";
CM_ SG_ 1885 checksum_1_8 "8 Bit checksum for protection of frame contents";
CM_ BO_ 1415 "Randomly defined CAN frame";
CM_ SG_ 1415 checksum_33_8 "8 Bit checksum for protection of frame contents";
CM_ BO_ 1252 "Randomly defined CAN frame";
CM_ SG_ 1252 checksum_25_8 "8 Bit checksum for protection of frame contents";
CM_ BO_ 947 "Randomly defined CAN frame";
CM_ SG_ 947 checksum_41_8 "8 Bit checksum for protection of frame contents";
CM_ BO_ 1334 "Randomly defined CAN frame";
CM_ SG_ 1334 checksum_41_8 "8 Bit checksum for protection of frame contents";
CM_ BO_ 458 "Randomly defined CAN frame";
CM_ SG_ 458 checksum_1_8 "8 Bit checksum for protection of frame contents";
CM_ BO_ 915 "Randomly defined CAN frame";
CM_ SG_ 915 checksum_25_8 "8 Bit checksum for protection of frame contents";
CM_ BO_ 349 "Randomly defined CAN frame";
CM_ SG_ 349 checksum_17_8 "8 Bit checksum for protection of frame contents";
CM_ BO_ 1 "Randomly defined CAN frame";
CM_ SG_ 1 checksum_1_8 "8 Bit checksum for protection of frame contents";
CM_ BO_ 435 "Randomly defined CAN frame";
CM_ SG_ 435 checksum_9_8 "8 Bit checksum for protection of frame contents";
CM_ BO_ 982 "Randomly defined CAN frame";
CM_ SG_ 982 checksum_1_8 "8 Bit checksum for protection of frame contents";
CM_ BO_ 263 "Randomly defined CAN frame";
CM_ SG_ 263 checksum_41_8 "8 Bit checksum for protection of frame contents";
BA_DEF_ "Author" STRING;
BA_DEF_ BO_ "frameSendMode" ENUM  "regular","event","mixed";
BA_DEF_ BO_ "sendPeriod" INT 5 10000;
BA_DEF_ BO_ "crcStartValue" INT 1 255;
BA_DEF_ BO_ "eventMinDistance" INT 5 10000;
BA_DEF_ SG_ "initialValue" FLOAT -1e38 1e38;
BA_DEF_DEF_ "Author" "http://sourceforge.net/projects/comframe/";
BA_DEF_DEF_ "frameSendMode" "regular";
BA_DEF_DEF_ "sendPeriod" 10;
BA_DEF_DEF_ "crcStartValue" 1;
BA_DEF_DEF_ "eventMinDistance" 10;
BA_DEF_DEF_ "initialValue" 0.0;
BA_ "frameSendMode" BO_ 1706 2;
BA_ "sendPeriod" BO_ 1706 100;
BA_ "eventMinDistance" BO_ 1706 100;
BA_ "crcStartValue" BO_ 1706 202;
BA_ "initialValue" SG_ 1706 sig_2_29 1.8121805800000025E-4;
BA_ "initialValue" SG_ 1706 sig_0_2 3.0;
BA_ "initialValue" SG_ 1706 sig_42_14 -1480.0;
BA_ "initialValue" SG_ 1706 sig_34_6 62.0;
BA_ "initialValue" SG_ 1706 sig_33_2 -1.0;
BA_ "sendPeriod" BO_ 1242 500;
BA_ "crcStartValue" BO_ 1242 122;
BA_ "initialValue" SG_ 1242 sig_4_10 -1.560000000000001E-4;
BA_ "initialValue" SG_ 1242 sig_7_3 -1.0;
BA_ "initialValue" SG_ 1242 sig_18_12 -2.4672776601683792;
BA_ "initialValue" SG_ 1242 sig_17_4 -3.0;
BA_ "initialValue" SG_ 1242 sig_40_10 0.044122776601683796;
BA_ "initialValue" SG_ 1242 sig_50_1 1.0;
BA_ "sendPeriod" BO_ 774 1000;
BA_ "crcStartValue" BO_ 774 208;
BA_ "initialValue" SG_ 774 sig_27_13 -0.09800000000000005;
BA_ "initialValue" SG_ 774 sig_9_8 -3.000000000000002E-4;
BA_ "initialValue" SG_ 774 sig_12_6 -32.0;
BA_ "initialValue" SG_ 774 sig_11_2 1.0;
BA_ "initialValue" SG_ 774 sig_24_3 6.0;
BA_ "initialValue" SG_ 774 sig_40_7 0.746227766016838;
BA_ "crcStartValue" BO_ 2044 86;
BA_ "initialValue" SG_ 2044 sig_0_14 1.7912776601683786E-5;
BA_ "initialValue" SG_ 2044 sig_15_2 1.0;
BA_ "initialValue" SG_ 2044 sig_31_2 -2.0;
BA_ "initialValue" SG_ 2044 sig_24_1 1.0;
BA_ "frameSendMode" BO_ 1907 2;
BA_ "sendPeriod" BO_ 1907 100;
BA_ "eventMinDistance" BO_ 1907 100;
BA_ "crcStartValue" BO_ 1907 229;
BA_ "initialValue" SG_ 1907 sig_31_1 1.0;
BA_ "initialValue" SG_ 1907 sig_15_16 -45.199776601683794;
BA_ "initialValue" SG_ 1907 sig_25_24 571.9131660168381;
BA_ "initialValue" SG_ 1907 sig_30_5 -2.0;
BA_ "sendPeriod" BO_ 594 50;
BA_ "crcStartValue" BO_ 594 226;
BA_ "initialValue" SG_ 594 sig_5_25 6821.580000000002;
BA_ "initialValue" SG_ 594 sig_1_4 6.16227766016838;
BA_ "initialValue" SG_ 594 sig_0_1 1.0;
BA_ "initialValue" SG_ 594 sig_30_2 -1.0;
BA_ "initialValue" SG_ 594 sig_47_16 -0.0021182000000000015;
BA_ "sendPeriod" BO_ 1049 5;
BA_ "crcStartValue" BO_ 1049 9;
BA_ "initialValue" SG_ 1049 sig_3_14 6.85727766016838;
BA_ "initialValue" SG_ 1049 sig_7_4 6.0;
BA_ "initialValue" SG_ 1049 sig_16_6 -22.0;
BA_ "initialValue" SG_ 1049 sig_30_13 10177.27766016838;
BA_ "initialValue" SG_ 1049 sig_28_5 -12.0;
BA_ "initialValue" SG_ 1049 sig_29_1 1.0;
BA_ "initialValue" SG_ 1049 sig_43_5 1100.0;
BA_ "sendPeriod" BO_ 1207 25;
BA_ "crcStartValue" BO_ 1207 218;
BA_ "initialValue" SG_ 1207 sig_19_31 -0.005797286500000006;
BA_ "initialValue" SG_ 1207 sig_9_10 -34900.0;
BA_ "initialValue" SG_ 1207 sig_8_1 1.0;
BA_ "initialValue" SG_ 1207 sig_55_4 -2.1622776601683786E-6;
BA_ "sendPeriod" BO_ 902 10000;
BA_ "crcStartValue" BO_ 902 5;
BA_ "initialValue" SG_ 902 sig_10_13 2.963277660168379E-6;
BA_ "initialValue" SG_ 902 sig_7_13 1022.0;
BA_ "initialValue" SG_ 902 sig_29_6 7.56227766016838;
BA_ "initialValue" SG_ 902 sig_46_13 484.1;
BA_ "initialValue" SG_ 902 sig_61_6 37.0;
BA_ "sendPeriod" BO_ 1834 100;
BA_ "crcStartValue" BO_ 1834 218;
BA_ "initialValue" SG_ 1834 sig_7_16 8.563000000000008E-6;
BA_ "initialValue" SG_ 1834 sig_28_20 0.05671012339831627;
BA_ "initialValue" SG_ 1834 sig_29_3 5.0;
BA_ "initialValue" SG_ 1834 sig_40_1 1.0;
BA_ "sendPeriod" BO_ 609 1000;
BA_ "crcStartValue" BO_ 609 104;
BA_ "initialValue" SG_ 609 sig_22_5 1.0;
BA_ "initialValue" SG_ 609 sig_8_8 -760.0;
BA_ "initialValue" SG_ 609 sig_16_2 3.0;
BA_ "initialValue" SG_ 609 sig_23_16 6655.0;
BA_ "sendPeriod" BO_ 1367 100;
BA_ "crcStartValue" BO_ 1367 167;
BA_ "initialValue" SG_ 1367 sig_21_16 0.7184000000000004;
BA_ "initialValue" SG_ 1367 sig_8_1 1.0;
BA_ "initialValue" SG_ 1367 sig_15_6 3562.2776601683795;
BA_ "initialValue" SG_ 1367 sig_9_1 1.0;
BA_ "initialValue" SG_ 1367 sig_22_2 2.0;
BA_ "initialValue" SG_ 1367 sig_37_5 17.0;
BA_ "initialValue" SG_ 1367 sig_32_1 1.0;
BA_ "initialValue" SG_ 1367 sig_50_14 140.80000000000004;
BA_ "initialValue" SG_ 1367 sig_48_2 -1.0;
BA_ "sendPeriod" BO_ 1053 500;
BA_ "crcStartValue" BO_ 1053 3;
BA_ "initialValue" SG_ 1053 sig_8_10 486.0;
BA_ "initialValue" SG_ 1053 sig_1_6 6.0;
BA_ "initialValue" SG_ 1053 sig_7_1 1.0;
BA_ "initialValue" SG_ 1053 sig_39_15 2.6170000000000013;
BA_ "sendPeriod" BO_ 1114 20;
BA_ "crcStartValue" BO_ 1114 142;
BA_ "initialValue" SG_ 1114 sig_6_16 -0.002962200000000002;
BA_ "initialValue" SG_ 1114 sig_16_7 0.021000000000000005;
BA_ "initialValue" SG_ 1114 sig_30_7 0.006900000000000003;
BA_ "initialValue" SG_ 1114 sig_46_11 1.3770000000000012E-5;
BA_ "initialValue" SG_ 1114 sig_48_4 38377.22339831621;
BA_ "sendPeriod" BO_ 693 20;
BA_ "crcStartValue" BO_ 693 184;
BA_ "initialValue" SG_ 693 sig_1_12 4.060000000000002E-4;
BA_ "initialValue" SG_ 693 sig_2_6 -2.8622776601683794E-5;
BA_ "initialValue" SG_ 693 sig_16_5 10.0;
BA_ "initialValue" SG_ 693 sig_21_1 1.0;
BA_ "initialValue" SG_ 693 sig_31_12 382.1;
BA_ "initialValue" SG_ 693 sig_32_4 6000.0;
BA_ "initialValue" SG_ 693 sig_48_11 -591.0;
BA_ "initialValue" SG_ 693 sig_63_5 0.14;
BA_ "sendPeriod" BO_ 1143 500;
BA_ "crcStartValue" BO_ 1143 99;
BA_ "initialValue" SG_ 1143 sig_8_13 0.9594277660168382;
BA_ "initialValue" SG_ 1143 sig_25_13 -7.940000000000007E-7;
BA_ "initialValue" SG_ 1143 sig_23_2 1.0;
BA_ "initialValue" SG_ 1143 sig_24_1 1.0;
BA_ "initialValue" SG_ 1143 sig_39_2 1.0;
BA_ "sendPeriod" BO_ 667 500;
BA_ "crcStartValue" BO_ 667 226;
BA_ "initialValue" SG_ 667 sig_22_35 4035.8350087683802;
BA_ "initialValue" SG_ 667 sig_9_6 6.66227766016838;
BA_ "initialValue" SG_ 667 sig_48_3 -3.0;
BA_ "sendPeriod" BO_ 453 1000;
BA_ "crcStartValue" BO_ 453 230;
BA_ "initialValue" SG_ 453 sig_19_10 3.647722339831626E-5;
BA_ "initialValue" SG_ 453 sig_8_10 667.0;
BA_ "initialValue" SG_ 453 sig_31_3 -2.0;
BA_ "initialValue" SG_ 453 sig_36_11 0.01474772233983163;
BA_ "initialValue" SG_ 453 sig_32_3 -4.0;
BA_ "frameSendMode" BO_ 1294 2;
BA_ "sendPeriod" BO_ 1294 100;
BA_ "eventMinDistance" BO_ 1294 100;
BA_ "crcStartValue" BO_ 1294 185;
BA_ "initialValue" SG_ 1294 sig_6_15 133.85000000000002;
BA_ "initialValue" SG_ 1294 sig_25_14 162.20000000000005;
BA_ "initialValue" SG_ 1294 sig_39_1 1.0;
BA_ "initialValue" SG_ 1294 sig_43_7 0.001037722339831623;
BA_ "initialValue" SG_ 1294 sig_41_7 3.400000000000002E-5;
BA_ "sendPeriod" BO_ 403 1000;
BA_ "crcStartValue" BO_ 403 92;
BA_ "initialValue" SG_ 403 sig_12_24 1.219657233983164E-5;
BA_ "initialValue" SG_ 403 sig_5_9 5.100000000000004E-6;
BA_ "initialValue" SG_ 403 sig_36_5 8.0;
BA_ "initialValue" SG_ 403 sig_48_9 -0.022522776601683787;
BA_ "initialValue" SG_ 403 sig_55_7 -21.622776601683793;
BA_ "sendPeriod" BO_ 1051 25;
BA_ "crcStartValue" BO_ 1051 97;
BA_ "initialValue" SG_ 1051 sig_12_5 25.0;
BA_ "initialValue" SG_ 1051 sig_6_9 9.800000000000008E-6;
BA_ "initialValue" SG_ 1051 sig_13_1 1.0;
BA_ "initialValue" SG_ 1051 sig_26_15 6821.0;
BA_ "initialValue" SG_ 1051 sig_24_1 1.0;
BA_ "initialValue" SG_ 1051 sig_41_7 0.008862277660168382;
BA_ "sendPeriod" BO_ 1352 50;
BA_ "crcStartValue" BO_ 1352 133;
BA_ "initialValue" SG_ 1352 sig_6_10 4.620000000000003E-4;
BA_ "initialValue" SG_ 1352 sig_30_7 114.0;
BA_ "initialValue" SG_ 1352 sig_8_5 17.0;
BA_ "initialValue" SG_ 1352 sig_16_8 2.0762277660168382;
BA_ "initialValue" SG_ 1352 sig_39_13 -1.7442776601683783E-4;
BA_ "initialValue" SG_ 1352 sig_40_3 2.0;
BA_ "frameSendMode" BO_ 1140 2;
BA_ "sendPeriod" BO_ 1140 1000;
BA_ "eventMinDistance" BO_ 1140 1000;
BA_ "crcStartValue" BO_ 1140 148;
BA_ "initialValue" SG_ 1140 sig_16_14 0.29242776601683795;
BA_ "initialValue" SG_ 1140 sig_3_11 957.0;
BA_ "initialValue" SG_ 1140 sig_40_16 -0.0021309000000000015;
BA_ "sendPeriod" BO_ 652 20;
BA_ "crcStartValue" BO_ 652 185;
BA_ "initialValue" SG_ 652 sig_10_2 2.0;
BA_ "initialValue" SG_ 652 sig_9_2 3.0;
BA_ "initialValue" SG_ 652 sig_34_11 0.004952277660168381;
BA_ "initialValue" SG_ 652 sig_32_2 1.0;
BA_ "initialValue" SG_ 652 sig_47_3 1.0;
BA_ "sendPeriod" BO_ 1091 100;
BA_ "crcStartValue" BO_ 1091 58;
BA_ "initialValue" SG_ 1091 sig_4_3 1.0;
BA_ "initialValue" SG_ 1091 sig_28_18 -7.556322339831629E-4;
BA_ "initialValue" SG_ 1091 sig_15_15 -7583.0;
BA_ "initialValue" SG_ 1091 sig_16_1 1.0;
BA_ "initialValue" SG_ 1091 sig_26_3 -4.0;
BA_ "initialValue" SG_ 1091 sig_47_2 -2.0;
BA_ "sendPeriod" BO_ 1715 50;
BA_ "crcStartValue" BO_ 1715 69;
BA_ "initialValue" SG_ 1715 sig_4_4 -111622.77660168378;
BA_ "initialValue" SG_ 1715 sig_1_9 294.0;
BA_ "initialValue" SG_ 1715 sig_8_5 3.1622776601683794E-4;
BA_ "initialValue" SG_ 1715 sig_16_1 1.0;
BA_ "initialValue" SG_ 1715 sig_32_14 -2818.2776601683795;
BA_ "crcStartValue" BO_ 766 167;
BA_ "initialValue" SG_ 766 sig_17_39 -17292.567561983782;
BA_ "sendPeriod" BO_ 131 1000;
BA_ "crcStartValue" BO_ 131 23;
BA_ "initialValue" SG_ 131 sig_19_14 2.7140000000000023E-6;
BA_ "initialValue" SG_ 131 sig_7_16 1229.0;
BA_ "initialValue" SG_ 131 sig_23_4 -0.008377223398316216;
BA_ "initialValue" SG_ 131 sig_37_6 -3.0;
BA_ "initialValue" SG_ 131 sig_52_11 231.0;
BA_ "initialValue" SG_ 131 sig_55_3 2.0;
BA_ "initialValue" SG_ 131 sig_53_2 1.0;
BA_ "crcStartValue" BO_ 1271 96;
BA_ "initialValue" SG_ 1271 sig_5_37 -3.23952514826838;
BA_ "sendPeriod" BO_ 332 20;
BA_ "crcStartValue" BO_ 332 118;
BA_ "initialValue" SG_ 332 sig_3_7 2.937722339831625E-6;
BA_ "initialValue" SG_ 332 sig_1_8 -9.162277660168383E-4;
BA_ "initialValue" SG_ 332 sig_31_16 27447.0;
BA_ "frameSendMode" BO_ 602 2;
BA_ "sendPeriod" BO_ 602 10000;
BA_ "eventMinDistance" BO_ 602 100;
BA_ "crcStartValue" BO_ 602 40;
BA_ "initialValue" SG_ 602 sig_40_15 0.045020000000000025;
BA_ "initialValue" SG_ 602 sig_9_12 31.100000000000005;
BA_ "initialValue" SG_ 602 sig_8_1 1.0;
BA_ "initialValue" SG_ 602 sig_21_19 3.3357300000000035E-6;
BA_ "initialValue" SG_ 602 sig_55_1 1.0;
BA_ "sendPeriod" BO_ 833 100;
BA_ "crcStartValue" BO_ 833 63;
BA_ "initialValue" SG_ 833 sig_11_6 -17.0;
BA_ "initialValue" SG_ 833 sig_1_7 42.0;
BA_ "initialValue" SG_ 833 sig_14_3 -1.0;
BA_ "initialValue" SG_ 833 sig_15_1 1.0;
BA_ "initialValue" SG_ 833 sig_16_6 18.0;
BA_ "initialValue" SG_ 833 sig_30_15 63.6477766016838;
BA_ "initialValue" SG_ 833 sig_55_7 -11.0;
BA_ "sendPeriod" BO_ 1605 50;
BA_ "crcStartValue" BO_ 1605 81;
BA_ "initialValue" SG_ 1605 sig_7_13 5661.0;
BA_ "initialValue" SG_ 1605 sig_9_9 54.0;
BA_ "initialValue" SG_ 1605 sig_10_1 1.0;
BA_ "initialValue" SG_ 1605 sig_39_13 2.5470000000000022E-5;
BA_ "initialValue" SG_ 1605 sig_41_8 -70.0;
BA_ "initialValue" SG_ 1605 sig_49_2 1.0;
BA_ "sendPeriod" BO_ 514 25;
BA_ "crcStartValue" BO_ 514 140;
BA_ "initialValue" SG_ 514 sig_30_17 38573.0;
BA_ "initialValue" SG_ 514 sig_14_11 -305.0;
BA_ "initialValue" SG_ 514 sig_19_5 -6622.776601683792;
BA_ "initialValue" SG_ 514 sig_40_14 85862.77660168378;
BA_ "initialValue" SG_ 514 sig_45_5 -0.09000000000000002;
BA_ "initialValue" SG_ 514 sig_58_3 4.0;
BA_ "frameSendMode" BO_ 1731 2;
BA_ "sendPeriod" BO_ 1731 10000;
BA_ "eventMinDistance" BO_ 1731 1000;
BA_ "crcStartValue" BO_ 1731 176;
BA_ "initialValue" SG_ 1731 sig_7_7 -1.9622776601683788E-5;
BA_ "initialValue" SG_ 1731 sig_0_1 1.0;
BA_ "initialValue" SG_ 1731 sig_24_29 -5.321656510168383E-6;
BA_ "initialValue" SG_ 1731 sig_22_10 282.0;
BA_ "initialValue" SG_ 1731 sig_59_4 0.2;
BA_ "sendPeriod" BO_ 1529 10000;
BA_ "crcStartValue" BO_ 1529 80;
BA_ "initialValue" SG_ 1529 sig_6_6 8.0;
BA_ "initialValue" SG_ 1529 sig_43_1 1.0;
BA_ "initialValue" SG_ 1529 sig_16_10 68.02277660168379;
BA_ "initialValue" SG_ 1529 sig_17_7 26.0;
BA_ "initialValue" SG_ 1529 sig_35_7 3.2377223398316244E-4;
BA_ "initialValue" SG_ 1529 sig_42_10 7.500000000000006E-5;
BA_ "sendPeriod" BO_ 417 50;
BA_ "crcStartValue" BO_ 417 189;
BA_ "initialValue" SG_ 417 sig_7_8 -0.46227766016837935;
BA_ "initialValue" SG_ 417 sig_16_14 -113.17223398316207;
BA_ "initialValue" SG_ 417 sig_21_5 0.0017000000000000008;
BA_ "initialValue" SG_ 417 sig_34_9 267.0;
BA_ "initialValue" SG_ 417 sig_41_2 2.0;
BA_ "frameSendMode" BO_ 808 2;
BA_ "sendPeriod" BO_ 808 1000;
BA_ "eventMinDistance" BO_ 808 100;
BA_ "crcStartValue" BO_ 808 32;
BA_ "initialValue" SG_ 808 sig_2_11 727.0;
BA_ "initialValue" SG_ 808 sig_0_2 2.0;
BA_ "initialValue" SG_ 808 sig_28_15 16.312776601683787;
BA_ "initialValue" SG_ 808 sig_24_3 -3.0;
BA_ "initialValue" SG_ 808 sig_43_5 25.0;
BA_ "sendPeriod" BO_ 1181 25;
BA_ "crcStartValue" BO_ 1181 213;
BA_ "initialValue" SG_ 1181 sig_10_19 -0.0022827976601683788;
BA_ "initialValue" SG_ 1181 sig_32_13 4883.0;
BA_ "initialValue" SG_ 1181 sig_47_3 3.0;
BA_ "sendPeriod" BO_ 1725 100;
BA_ "crcStartValue" BO_ 1725 82;
BA_ "initialValue" SG_ 1725 sig_7_8 128377.22339831622;
BA_ "initialValue" SG_ 1725 sig_5_7 0.0032377223398316235;
BA_ "initialValue" SG_ 1725 sig_17_7 8.200000000000006E-6;
BA_ "initialValue" SG_ 1725 sig_35_12 12190.0;
BA_ "initialValue" SG_ 1725 sig_36_4 83.77223398316204;
BA_ "sendPeriod" BO_ 208 5;
BA_ "crcStartValue" BO_ 208 104;
BA_ "initialValue" SG_ 208 sig_7_8 -0.8800000000000001;
BA_ "initialValue" SG_ 208 sig_24_13 3.311000000000001;
BA_ "initialValue" SG_ 208 sig_39_2 2.0;
BA_ "initialValue" SG_ 208 sig_47_8 4400.0;
BA_ "sendPeriod" BO_ 1246 10000;
BA_ "crcStartValue" BO_ 1246 5;
BA_ "initialValue" SG_ 1246 sig_7_8 0.09662277660168381;
BA_ "initialValue" SG_ 1246 sig_24_15 -7394.0;
BA_ "initialValue" SG_ 1246 sig_22_5 40.622776601683796;
BA_ "initialValue" SG_ 1246 sig_17_2 -2.0;
BA_ "sendPeriod" BO_ 1423 100;
BA_ "crcStartValue" BO_ 1423 91;
BA_ "initialValue" SG_ 1423 sig_1_8 159.0;
BA_ "initialValue" SG_ 1423 sig_0_1 1.0;
BA_ "initialValue" SG_ 1423 sig_10_4 7.1622776601683816E-6;
BA_ "initialValue" SG_ 1423 sig_14_1 1.0;
BA_ "initialValue" SG_ 1423 sig_26_13 -9067.223398316208;
BA_ "frameSendMode" BO_ 2018 2;
BA_ "sendPeriod" BO_ 2018 50;
BA_ "eventMinDistance" BO_ 2018 50;
BA_ "crcStartValue" BO_ 2018 189;
BA_ "initialValue" SG_ 2018 sig_22_23 -0.025435246601683788;
BA_ "initialValue" SG_ 2018 sig_5_15 0.002845677660168379;
BA_ "initialValue" SG_ 2018 sig_3_3 -1.0;
BA_ "initialValue" SG_ 2018 sig_0_1 1.0;
BA_ "initialValue" SG_ 2018 sig_4_1 1.0;
BA_ "initialValue" SG_ 2018 sig_20_2 1.0;
BA_ "initialValue" SG_ 2018 sig_54_2 2.0;
BA_ "sendPeriod" BO_ 846 50;
BA_ "crcStartValue" BO_ 846 193;
BA_ "initialValue" SG_ 846 sig_2_15 22723.0;
BA_ "initialValue" SG_ 846 sig_23_5 0.02162277660168379;
BA_ "initialValue" SG_ 846 sig_17_1 1.0;
BA_ "initialValue" SG_ 846 sig_25_7 16.0;
BA_ "initialValue" SG_ 846 sig_24_1 1.0;
BA_ "initialValue" SG_ 846 sig_47_15 -3.70677766016838E-4;
BA_ "frameSendMode" BO_ 1764 2;
BA_ "sendPeriod" BO_ 1764 10000;
BA_ "eventMinDistance" BO_ 1764 1000;
BA_ "crcStartValue" BO_ 1764 34;
BA_ "initialValue" SG_ 1764 sig_21_14 -0.002484277660168379;
BA_ "initialValue" SG_ 1764 sig_7_16 718.0;
BA_ "initialValue" SG_ 1764 sig_23_2 2.0;
BA_ "initialValue" SG_ 1764 sig_47_13 -3759.0;
BA_ "initialValue" SG_ 1764 sig_50_2 2.0;
BA_ "initialValue" SG_ 1764 sig_48_1 1.0;
BA_ "frameSendMode" BO_ 1412 1;
BA_ "eventMinDistance" BO_ 1412 500;
BA_ "crcStartValue" BO_ 1412 183;
BA_ "initialValue" SG_ 1412 sig_10_8 9.500000000000005E-4;
BA_ "initialValue" SG_ 1412 sig_8_2 1.0;
BA_ "initialValue" SG_ 1412 sig_23_6 4.1000000000000026E-4;
BA_ "initialValue" SG_ 1412 sig_27_8 -0.013622776601683786;
BA_ "initialValue" SG_ 1412 sig_25_2 2.0;
BA_ "initialValue" SG_ 1412 sig_36_2 1.0;
BA_ "frameSendMode" BO_ 1445 2;
BA_ "sendPeriod" BO_ 1445 1000;
BA_ "eventMinDistance" BO_ 1445 50;
BA_ "crcStartValue" BO_ 1445 211;
BA_ "initialValue" SG_ 1445 sig_10_9 506.0;
BA_ "initialValue" SG_ 1445 sig_0_8 -1.0800000000000008E-5;
BA_ "initialValue" SG_ 1445 sig_15_5 3000.0;
BA_ "initialValue" SG_ 1445 sig_29_15 -6.870000000000006E-5;
BA_ "initialValue" SG_ 1445 sig_17_2 3.0;
BA_ "initialValue" SG_ 1445 sig_46_5 22.0;
BA_ "initialValue" SG_ 1445 sig_56_7 24377.223398316208;
BA_ "initialValue" SG_ 1445 sig_63_1 1.0;
BA_ "sendPeriod" BO_ 590 10000;
BA_ "crcStartValue" BO_ 590 47;
BA_ "initialValue" SG_ 590 sig_5_15 10445.0;
BA_ "initialValue" SG_ 590 sig_17_4 837.7223398316205;
BA_ "initialValue" SG_ 590 sig_22_2 1.0;
BA_ "initialValue" SG_ 590 sig_30_7 -4862.27766016838;
BA_ "initialValue" SG_ 590 sig_40_16 634.4776601683793;
BA_ "frameSendMode" BO_ 442 2;
BA_ "sendPeriod" BO_ 442 1000;
BA_ "eventMinDistance" BO_ 442 1000;
BA_ "crcStartValue" BO_ 442 207;
BA_ "initialValue" SG_ 442 sig_1_12 143.0;
BA_ "initialValue" SG_ 442 sig_3_4 13.0;
BA_ "initialValue" SG_ 442 sig_16_1 1.0;
BA_ "initialValue" SG_ 442 sig_29_6 4000.0;
BA_ "initialValue" SG_ 442 sig_46_7 3.96227766016838;
BA_ "initialValue" SG_ 442 sig_45_9 171.0;
BA_ "sendPeriod" BO_ 672 25;
BA_ "crcStartValue" BO_ 672 158;
BA_ "initialValue" SG_ 672 sig_37_16 -3347.0;
BA_ "initialValue" SG_ 672 sig_10_6 536.2277660168379;
BA_ "initialValue" SG_ 672 sig_0_8 -2.7622776601683796;
BA_ "initialValue" SG_ 672 sig_15_5 4362.27766016838;
BA_ "initialValue" SG_ 672 sig_16_7 23.0;
BA_ "initialValue" SG_ 672 sig_25_2 1.0;
BA_ "initialValue" SG_ 672 sig_32_5 27.0;
BA_ "sendPeriod" BO_ 1419 5;
BA_ "crcStartValue" BO_ 1419 155;
BA_ "initialValue" SG_ 1419 sig_8_8 69.0;
BA_ "initialValue" SG_ 1419 sig_0_7 -35.0;
BA_ "initialValue" SG_ 1419 sig_7_1 1.0;
BA_ "initialValue" SG_ 1419 sig_23_7 0.00386227766016838;
BA_ "initialValue" SG_ 1419 sig_32_4 1.1000000000000006E-5;
BA_ "sendPeriod" BO_ 1937 50;
BA_ "crcStartValue" BO_ 1937 38;
BA_ "initialValue" SG_ 1937 sig_24_17 -0.013310000000000008;
BA_ "initialValue" SG_ 1937 sig_18_8 0.017200000000000007;
BA_ "initialValue" SG_ 1937 sig_15_9 616.2277660168379;
BA_ "initialValue" SG_ 1937 sig_22_4 14.0;
BA_ "initialValue" SG_ 1937 sig_49_4 -8.0;
BA_ "initialValue" SG_ 1937 sig_53_3 -3.0;
BA_ "sendPeriod" BO_ 1630 50;
BA_ "crcStartValue" BO_ 1630 176;
BA_ "initialValue" SG_ 1630 sig_40_7 82.0;
BA_ "initialValue" SG_ 1630 sig_6_15 605.4377660168379;
BA_ "initialValue" SG_ 1630 sig_7_1 1.0;
BA_ "initialValue" SG_ 1630 sig_16_14 3551.0;
BA_ "initialValue" SG_ 1630 sig_47_1 1.0;
BA_ "sendPeriod" BO_ 718 5;
BA_ "crcStartValue" BO_ 718 107;
BA_ "initialValue" SG_ 718 sig_7_10 44.07722339831621;
BA_ "initialValue" SG_ 718 sig_10_4 2.0;
BA_ "initialValue" SG_ 718 sig_32_17 16241.0;
BA_ "initialValue" SG_ 718 sig_24_8 44.0;
BA_ "initialValue" SG_ 718 sig_33_6 -6.06227766016838;
BA_ "sendPeriod" BO_ 1042 25;
BA_ "crcStartValue" BO_ 1042 254;
BA_ "initialValue" SG_ 1042 sig_10_21 0.07391302339831629;
BA_ "initialValue" SG_ 1042 sig_8_2 2.0;
BA_ "initialValue" SG_ 1042 sig_35_12 900.0;
BA_ "initialValue" SG_ 1042 sig_47_7 1.1962277660168384E-4;
BA_ "initialValue" SG_ 1042 sig_54_2 -2.0;
BA_ "frameSendMode" BO_ 2013 2;
BA_ "sendPeriod" BO_ 2013 500;
BA_ "eventMinDistance" BO_ 2013 500;
BA_ "crcStartValue" BO_ 2013 233;
BA_ "initialValue" SG_ 2013 sig_7_17 4.488300000000004E-4;
BA_ "initialValue" SG_ 2013 sig_0_7 5.73772233983162;
BA_ "initialValue" SG_ 2013 sig_24_8 2546.227766016838;
BA_ "initialValue" SG_ 2013 sig_40_15 0.10260000000000007;
BA_ "initialValue" SG_ 2013 sig_56_8 0.17000000000000004;
BA_ "frameSendMode" BO_ 1473 2;
BA_ "sendPeriod" BO_ 1473 1000;
BA_ "eventMinDistance" BO_ 1473 50;
BA_ "crcStartValue" BO_ 1473 87;
BA_ "initialValue" SG_ 1473 sig_3_9 -2.3000000000000017E-5;
BA_ "initialValue" SG_ 1473 sig_4_7 52.0;
BA_ "initialValue" SG_ 1473 sig_24_16 5.2782776601683805;
BA_ "initialValue" SG_ 1473 sig_47_16 5.986977660168382E-5;
BA_ "sendPeriod" BO_ 1033 25;
BA_ "crcStartValue" BO_ 1033 217;
BA_ "initialValue" SG_ 1033 sig_0_8 -6.66227766016838;
BA_ "initialValue" SG_ 1033 sig_17_9 161.0;
BA_ "initialValue" SG_ 1033 sig_20_4 0.0031622776601683794;
BA_ "initialValue" SG_ 1033 sig_32_4 13.0;
BA_ "frameSendMode" BO_ 803 2;
BA_ "sendPeriod" BO_ 803 100;
BA_ "eventMinDistance" BO_ 803 50;
BA_ "crcStartValue" BO_ 803 133;
BA_ "initialValue" SG_ 803 sig_1_10 1214.227766016838;
BA_ "initialValue" SG_ 803 sig_0_6 0.03362277660168379;
BA_ "initialValue" SG_ 803 sig_24_8 -85.0;
BA_ "sendPeriod" BO_ 779 25;
BA_ "crcStartValue" BO_ 779 215;
BA_ "initialValue" SG_ 779 sig_3_11 -0.802227766016838;
BA_ "initialValue" SG_ 779 sig_4_5 -1.7622776601683782E-6;
BA_ "initialValue" SG_ 779 sig_24_12 1956.0;
BA_ "initialValue" SG_ 779 sig_29_3 3.0;
BA_ "initialValue" SG_ 779 sig_30_1 1.0;
BA_ "initialValue" SG_ 779 sig_40_4 200.0;
BA_ "initialValue" SG_ 779 sig_55_8 2637.7223398316205;
BA_ "frameSendMode" BO_ 106 2;
BA_ "sendPeriod" BO_ 106 1000;
BA_ "eventMinDistance" BO_ 106 500;
BA_ "crcStartValue" BO_ 106 101;
BA_ "initialValue" SG_ 106 sig_7_11 218.0227766016838;
BA_ "initialValue" SG_ 106 sig_8_5 -0.0013000000000000006;
BA_ "initialValue" SG_ 106 sig_29_14 64597.22339831621;
BA_ "initialValue" SG_ 106 sig_30_2 -2.0;
BA_ "sendPeriod" BO_ 905 500;
BA_ "crcStartValue" BO_ 905 13;
BA_ "initialValue" SG_ 905 sig_2_14 1.0412722339831634E-4;
BA_ "initialValue" SG_ 905 sig_0_2 2.0;
BA_ "initialValue" SG_ 905 sig_47_13 1326.2776601683795;
BA_ "initialValue" SG_ 905 sig_27_5 2.0;
BA_ "initialValue" SG_ 905 sig_31_8 68.0;
BA_ "initialValue" SG_ 905 sig_28_3 4.0;
BA_ "initialValue" SG_ 905 sig_48_3 2.0;
BA_ "initialValue" SG_ 905 sig_58_6 -0.30000000000000004;
BA_ "initialValue" SG_ 905 sig_56_2 1.0;
BA_ "crcStartValue" BO_ 877 118;
BA_ "initialValue" SG_ 877 sig_7_7 -2337.7223398316205;
BA_ "initialValue" SG_ 877 sig_0_1 1.0;
BA_ "initialValue" SG_ 877 sig_20_7 8.762277660168382E-5;
BA_ "initialValue" SG_ 877 sig_21_9 2.5;
BA_ "sendPeriod" BO_ 489 100;
BA_ "crcStartValue" BO_ 489 52;
BA_ "initialValue" SG_ 489 sig_5_6 2.9000000000000017E-5;
BA_ "initialValue" SG_ 489 sig_0_5 4.000000000000002E-4;
BA_ "initialValue" SG_ 489 sig_11_20 93651.1766016838;
BA_ "initialValue" SG_ 489 sig_33_7 88622.77660168378;
BA_ "initialValue" SG_ 489 sig_52_2 1.0;
BA_ "initialValue" SG_ 489 sig_54_2 2.0;
BA_ "sendPeriod" BO_ 1758 25;
BA_ "crcStartValue" BO_ 1758 11;
BA_ "initialValue" SG_ 1758 sig_6_16 22179.0;
BA_ "initialValue" SG_ 1758 sig_7_1 1.0;
BA_ "initialValue" SG_ 1758 sig_16_7 -88622.77660168378;
BA_ "initialValue" SG_ 1758 sig_39_8 4.622776601683793;
BA_ "sendPeriod" BO_ 1998 25;
BA_ "crcStartValue" BO_ 1998 24;
BA_ "initialValue" SG_ 1998 sig_11_13 1.526722339831624E-4;
BA_ "initialValue" SG_ 1998 sig_8_1 1.0;
BA_ "initialValue" SG_ 1998 sig_30_24 9.911454660168386E-5;
BA_ "initialValue" SG_ 1998 sig_54_7 -93.6227766016838;
BA_ "sendPeriod" BO_ 1324 500;
BA_ "crcStartValue" BO_ 1324 172;
BA_ "initialValue" SG_ 1324 sig_7_5 0.005000000000000001;
BA_ "sendPeriod" BO_ 1885 100;
BA_ "crcStartValue" BO_ 1885 12;
BA_ "initialValue" SG_ 1885 sig_13_13 696.0;
BA_ "initialValue" SG_ 1885 sig_15_2 -1.0;
BA_ "initialValue" SG_ 1885 sig_31_8 166.0;
BA_ "initialValue" SG_ 1885 sig_16_1 1.0;
BA_ "frameSendMode" BO_ 1415 2;
BA_ "sendPeriod" BO_ 1415 1000;
BA_ "eventMinDistance" BO_ 1415 100;
BA_ "crcStartValue" BO_ 1415 95;
BA_ "initialValue" SG_ 1415 sig_9_12 -874.0;
BA_ "initialValue" SG_ 1415 sig_0_4 12000.0;
BA_ "initialValue" SG_ 1415 sig_11_5 -4.26227766016838E-4;
BA_ "initialValue" SG_ 1415 sig_10_1 1.0;
BA_ "initialValue" SG_ 1415 sig_29_5 5162.27766016838;
BA_ "initialValue" SG_ 1415 sig_24_1 1.0;
BA_ "frameSendMode" BO_ 1252 2;
BA_ "sendPeriod" BO_ 1252 1000;
BA_ "eventMinDistance" BO_ 1252 500;
BA_ "crcStartValue" BO_ 1252 92;
BA_ "initialValue" SG_ 1252 sig_2_17 12377.776601683792;
BA_ "initialValue" SG_ 1252 sig_0_2 -1.0;
BA_ "initialValue" SG_ 1252 sig_23_5 14.0;
BA_ "initialValue" SG_ 1252 sig_39_7 0.0756227766016838;
BA_ "sendPeriod" BO_ 947 10000;
BA_ "crcStartValue" BO_ 947 204;
BA_ "initialValue" SG_ 947 sig_27_4 -0.31622776601683794;
BA_ "initialValue" SG_ 947 sig_7_2 -1.0;
BA_ "initialValue" SG_ 947 sig_17_6 0.006862277660168382;
BA_ "initialValue" SG_ 947 sig_30_3 2.0;
BA_ "initialValue" SG_ 947 sig_16_2 1.0;
BA_ "initialValue" SG_ 947 sig_32_8 118.0;
BA_ "initialValue" SG_ 947 sig_49_15 10492.0;
BA_ "initialValue" SG_ 947 sig_48_1 1.0;
BA_ "sendPeriod" BO_ 1334 500;
BA_ "crcStartValue" BO_ 1334 7;
BA_ "initialValue" SG_ 1334 sig_30_10 396.22776601683796;
BA_ "initialValue" SG_ 1334 sig_10_9 105.0;
BA_ "initialValue" SG_ 1334 sig_6_3 3.0;
BA_ "initialValue" SG_ 1334 sig_1_3 1.0;
BA_ "initialValue" SG_ 1334 sig_7_1 1.0;
BA_ "initialValue" SG_ 1334 sig_23_5 -5.0;
BA_ "initialValue" SG_ 1334 sig_8_2 1.0;
BA_ "initialValue" SG_ 1334 sig_25_5 160.0;
BA_ "initialValue" SG_ 1334 sig_24_1 1.0;
BA_ "frameSendMode" BO_ 458 2;
BA_ "sendPeriod" BO_ 458 10000;
BA_ "eventMinDistance" BO_ 458 50;
BA_ "crcStartValue" BO_ 458 54;
BA_ "initialValue" SG_ 458 sig_17_31 142352.86590168384;
BA_ "initialValue" SG_ 458 sig_15_6 4262.27766016838;
BA_ "initialValue" SG_ 458 sig_53_5 0.005562277660168381;
BA_ "initialValue" SG_ 458 sig_55_1 1.0;
BA_ "frameSendMode" BO_ 915 2;
BA_ "sendPeriod" BO_ 915 100;
BA_ "eventMinDistance" BO_ 915 100;
BA_ "crcStartValue" BO_ 915 205;
BA_ "initialValue" SG_ 915 sig_1_12 0.002361277660168379;
BA_ "initialValue" SG_ 915 sig_36_13 6.545277660168382E-5;
BA_ "initialValue" SG_ 915 sig_39_2 1.0;
BA_ "initialValue" SG_ 915 sig_37_1 1.0;
BA_ "sendPeriod" BO_ 349 25;
BA_ "crcStartValue" BO_ 349 39;
BA_ "initialValue" SG_ 349 sig_3_13 -3.5582776601683797E-6;
BA_ "initialValue" SG_ 349 sig_2_3 1.0;
BA_ "initialValue" SG_ 349 sig_28_10 -4.99227766016838E-4;
BA_ "initialValue" SG_ 349 sig_46_7 -35.0;
BA_ "initialValue" SG_ 349 sig_47_1 1.0;
BA_ "frameSendMode" BO_ 1 2;
BA_ "sendPeriod" BO_ 1 1000;
BA_ "eventMinDistance" BO_ 1 500;
BA_ "crcStartValue" BO_ 1 76;
BA_ "initialValue" SG_ 1 sig_13_13 -2810.2776601683795;
BA_ "initialValue" SG_ 1 sig_15_2 3.0;
BA_ "sendPeriod" BO_ 435 1000;
BA_ "crcStartValue" BO_ 435 248;
BA_ "initialValue" SG_ 435 sig_1_6 -2062.2776601683795;
BA_ "initialValue" SG_ 435 sig_0_1 1.0;
BA_ "initialValue" SG_ 435 sig_7_1 1.0;
BA_ "initialValue" SG_ 435 sig_27_19 2.5678600000000027E-6;
BA_ "initialValue" SG_ 435 sig_23_8 16100.0;
BA_ "initialValue" SG_ 435 sig_26_3 6.0;
BA_ "initialValue" SG_ 435 sig_46_2 -1.0;
BA_ "sendPeriod" BO_ 982 20;
BA_ "crcStartValue" BO_ 982 153;
BA_ "initialValue" SG_ 982 sig_13_23 5.2354896601683815E-5;
BA_ "initialValue" SG_ 982 sig_37_18 72840.0;
BA_ "initialValue" SG_ 982 sig_38_1 1.0;
BA_ "initialValue" SG_ 982 sig_51_3 -4.0;
BA_ "sendPeriod" BO_ 263 1000;
BA_ "crcStartValue" BO_ 263 70;
BA_ "initialValue" SG_ 263 sig_0_15 22539.0;
BA_ "initialValue" SG_ 263 sig_15_19 3.743100000000004E-5;
BA_ "initialValue" SG_ 263 sig_38_3 5.0;
BA_ "initialValue" SG_ 263 sig_52_7 -260.0;
BA_ "initialValue" SG_ 263 sig_54_6 8.262277660168384E-5;
BA_ "initialValue" SG_ 263 sig_53_1 1.0;
BA_ "initialValue" SG_ 263 sig_61_2 1.0;
